VERSION ""

NS_ :

BS_:

BU_: ACC ACP Aux_Inv BEQ BMS BRC CAMERA CCS CLU CLUSTER CM CRSH EBS ECAS EHP EHPS_Hi_OilPump EHPS_Lo_OilPump EWP_1 EWP_2 EWP_3 FAM LDC MFC MFSM RAM TBOX TCU Tester VCU

BO_ 1298 VCU_HMU: 8 VCU
 SG_ CF_Vcu_H2TnkVlv1Open : 0|1@1+ (1,0) [0|1] "" Vector__XXX
 SG_ CF_Vcu_H2TnkVlv2Open : 1|1@1+ (1,0) [0|1] "" Vector__XXX
 SG_ CF_Vcu_H2TnkVlv3Open : 2|1@1+ (1,0) [0|1] "" Vector__XXX
 SG_ CF_Vcu_H2TnkVlv4Open : 3|1@1+ (1,0) [0|1] "" Vector__XXX
 SG_ CF_Vcu_H2TnkVlv5Open : 4|1@1+ (1,0) [0|1] "" Vector__XXX
 SG_ CF_Vcu_H2TnkVlv6Open : 5|1@1+ (1,0) [0|1] "" Vector__XXX
 SG_ CF_Vcu_H2TnkVlv7Open : 6|1@1+ (1,0) [0|1] "" Vector__XXX
 SG_ CF_Vcu_H2TnkVlv8Open : 7|1@1+ (1,0) [0|1] "" Vector__XXX
 SG_ CF_Vcu_VehSt : 8|1@1+ (1,0) [0|1] "" Vector__XXX
 SG_ CF_Vcu_VehWu : 9|1@1+ (1,0) [0|1] "" Vector__XXX
 SG_ CF_Vcu_VehHybFcMde : 10|1@1+ (1,0) [0|1] "" Vector__XXX
 SG_ CF_Vcu_FuelDrOpnUn : 11|1@1+ (1,0) [0|1] "" Vector__XXX
 SG_ CR_Vcu_VehStpHr : 16|8@1+ (1,0) [0|255] "" Vector__XXX
 SG_ CF_Vcu_H2TnkVlv9Open : 24|1@1+ (1,0) [0|1] "" Vector__XXX
 SG_ CF_Vcu_H2TnkVlv10Open : 25|1@1+ (1,0) [0|1] "" Vector__XXX
 SG_ CF_Vcu_H2TnkVlv11Open : 26|1@1+ (1,0) [0|1] "" Vector__XXX
 SG_ CF_Vcu_H2TnkVlv12Open : 27|1@1+ (1,0) [0|1] "" Vector__XXX

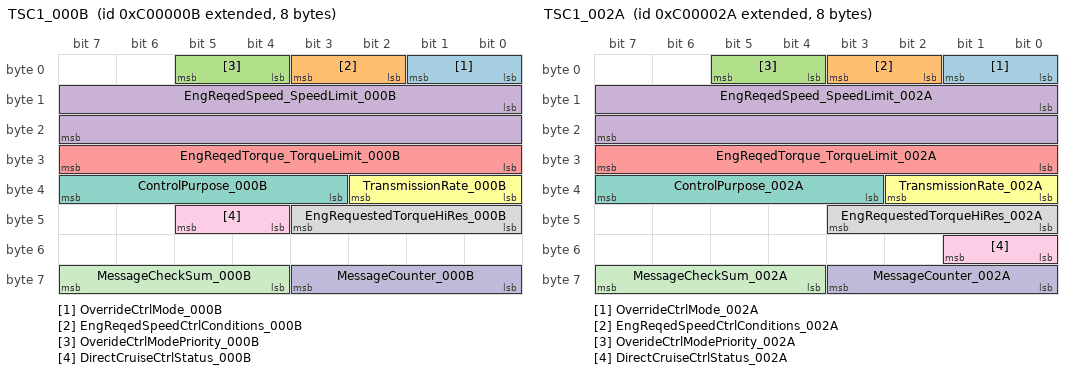
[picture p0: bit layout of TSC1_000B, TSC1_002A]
BO_ 2348810251 TSC1_000B: 8 EBS
 SG_ OverrideCtrlMode_000B : 0|2@1+ (1,0) [0|3] "" VCU
 SG_ EngReqedSpeedCtrlConditions_000B : 2|2@1+ (1,0) [0|3] "" VCU
 SG_ OverideCtrlModePriority_000B : 4|2@1+ (1,0) [0|3] "" VCU
 SG_ EngReqedSpeed_SpeedLimit_000B : 8|16@1+ (0.125,0) [0|8031.88] "rpm" VCU
 SG_ EngReqedTorque_TorqueLimit_000B : 24|8@1+ (1,-125) [-125|125] "%" VCU
 SG_ TransmissionRate_000B : 32|3@1+ (1,0) [0|7] "" VCU
 SG_ ControlPurpose_000B : 35|5@1+ (1,0) [0|31] "" VCU
 SG_ EngRequestedTorqueHiRes_000B : 40|4@1+ (0.125,0) [0|0.875] "%" VCU
 SG_ DirectCruiseCtrlStatus_000B : 44|2@1+ (1,0) [0|3] "" VCU
 SG_ MessageCounter_000B : 56|4@1+ (1,0) [0|15] "" VCU
 SG_ MessageCheckSum_000B : 60|4@1+ (1,0) [0|15] "" VCU

BO_ 2348810282 TSC1_002A: 8 ACC
 SG_ OverrideCtrlMode_002A : 0|2@1+ (1,0) [0|3] "" VCU
 SG_ EngReqedSpeedCtrlConditions_002A : 2|2@1+ (1,0) [0|3] "" VCU
 SG_ OverideCtrlModePriority_002A : 4|2@1+ (1,0) [0|3] "" VCU
 SG_ EngReqedSpeed_SpeedLimit_002A : 8|16@1+ (0.125,0) [0|8031.88] "rpm" VCU
 SG_ EngReqedTorque_TorqueLimit_002A : 24|8@1+ (1,-125) [-125|125] "%" VCU
 SG_ TransmissionRate_002A : 32|3@1+ (1,0) [0|7] "" VCU
 SG_ ControlPurpose_002A : 35|5@1+ (1,0) [0|31] "" VCU
 SG_ EngRequestedTorqueHiRes_002A : 40|4@1+ (0.125,0) [0|0.875] "%" VCU
 SG_ DirectCruiseCtrlStatus_002A : 48|2@1+ (1,0) [0|3] "" VCU
 SG_ MessageCounter_002A : 56|4@1+ (1,0) [0|15] "" VCU
 SG_ MessageCheckSum_002A : 60|4@1+ (1,0) [0|15] "" VCU

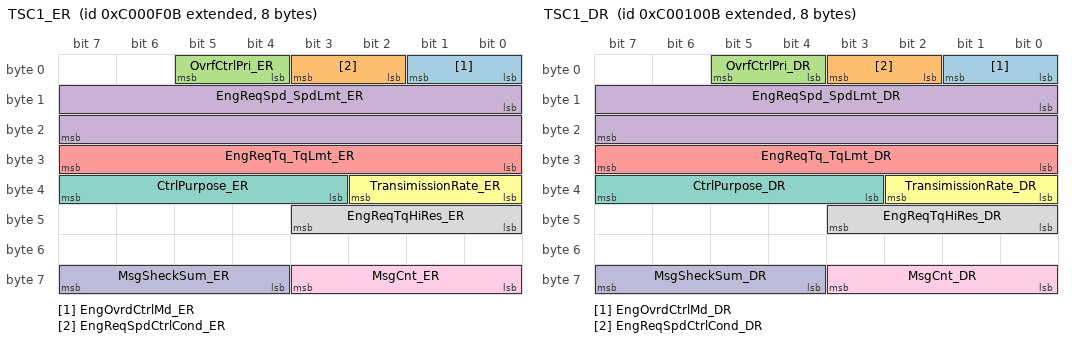
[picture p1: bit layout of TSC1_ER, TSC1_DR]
BO_ 2348814091 TSC1_ER: 8 EBS
 SG_ EngOvrdCtrlMd_ER : 0|2@1+ (1,0) [0|3] "" VCU
 SG_ EngReqSpdCtrlCond_ER : 2|2@1+ (1,0) [0|3] "" VCU
 SG_ OvrfCtrlPri_ER : 4|2@1+ (1,0) [0|3] "" VCU
 SG_ EngReqSpd_SpdLmt_ER : 8|16@1+ (0.125,0) [0|8031.88] "" VCU
 SG_ EngReqTq_TqLmt_ER : 24|8@1+ (1,-125) [-125|125] "" VCU
 SG_ TransimissionRate_ER : 32|3@1+ (1,0) [0|7] "" VCU
 SG_ CtrlPurpose_ER : 35|5@1+ (1,0) [0|31] "" VCU
 SG_ EngReqTqHiRes_ER : 40|4@1+ (0.125,0) [0|0.875] "" VCU
 SG_ MsgCnt_ER : 56|4@1+ (1,0) [0|15] "" VCU
 SG_ MsgSheckSum_ER : 60|4@1+ (1,0) [0|15] "" VCU

BO_ 2348814347 TSC1_DR: 8 EBS
 SG_ EngOvrdCtrlMd_DR : 0|2@1+ (1,0) [0|3] "" VCU
 SG_ EngReqSpdCtrlCond_DR : 2|2@1+ (1,0) [0|3] "" VCU
 SG_ OvrfCtrlPri_DR : 4|2@1+ (1,0) [0|3] "" VCU
 SG_ EngReqSpd_SpdLmt_DR : 8|16@1+ (0.125,0) [0|8031.88] "" VCU
 SG_ EngReqTq_TqLmt_DR : 24|8@1+ (1,-125) [-125|125] "" VCU
 SG_ TransimissionRate_DR : 32|3@1+ (1,0) [0|7] "" VCU
 SG_ CtrlPurpose_DR : 35|5@1+ (1,0) [0|31] "" VCU
 SG_ EngReqTqHiRes_DR : 40|4@1+ (0.125,0) [0|0.875] "" VCU
 SG_ MsgCnt_DR : 56|4@1+ (1,0) [0|15] "" VCU
 SG_ MsgSheckSum_DR : 60|4@1+ (1,0) [0|15] "" VCU

BO_ 2348876549 TC1_EATON: 8 MFSM
 SG_ TransmissionRequestedGear : 16|8@1+ (1,0) [0|255] "" VCU

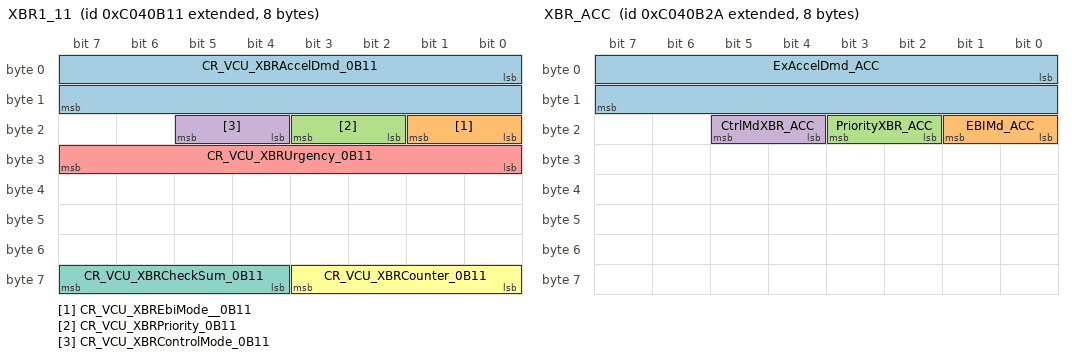
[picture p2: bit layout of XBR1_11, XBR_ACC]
BO_ 2349075217 XBR1_11: 8 VCU
 SG_ CR_VCU_XBRAccelDmd_0B11 : 0|16@1+ (0.000488281,-15.687) [-15.687|15.687] "" EBS
 SG_ CR_VCU_XBREbiMode__0B11 : 16|2@1+ (1,0) [0|3] "" EBS
 SG_ CR_VCU_XBRPriority_0B11 : 18|2@1+ (1,0) [0|3] "" EBS
 SG_ CR_VCU_XBRControlMode_0B11 : 20|2@1+ (1,0) [0|3] "" EBS
 SG_ CR_VCU_XBRUrgency_0B11 : 24|8@1+ (0.4,0) [0|100] "" EBS
 SG_ CR_VCU_XBRCounter_0B11 : 56|4@1+ (1,0) [0|15] "" EBS
 SG_ CR_VCU_XBRCheckSum_0B11 : 60|4@1+ (1,0) [0|15] "" EBS

BO_ 2349075242 XBR_ACC: 8 ACC
 SG_ ExAccelDmd_ACC : 0|16@1+ (0.0004883,-15.687) [-15.687|15.687] "" VCU
 SG_ EBIMd_ACC : 16|2@1+ (1,0) [0|2] "" VCU
 SG_ PriorityXBR_ACC : 18|2@1+ (1,0) [0|2] "" VCU
 SG_ CtrlMdXBR_ACC : 20|2@1+ (1,0) [0|2] "" VCU

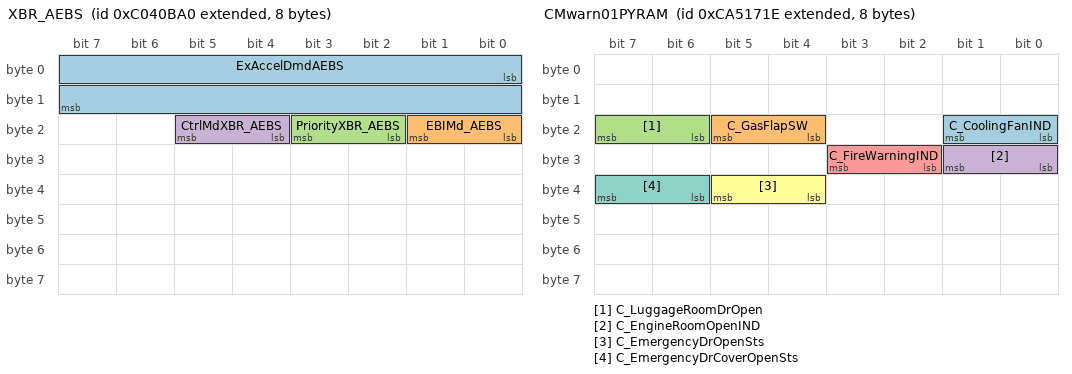
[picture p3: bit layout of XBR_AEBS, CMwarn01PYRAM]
BO_ 2349075360 XBR_AEBS: 8 CAMERA
 SG_ ExAccelDmdAEBS : 0|16@1+ (0.0004883,-15.687) [-15.687|15.687] "" VCU
 SG_ EBIMd_AEBS : 16|2@1+ (1,0) [0|2] "" VCU
 SG_ PriorityXBR_AEBS : 18|2@1+ (1,0) [0|2] "" VCU
 SG_ CtrlMdXBR_AEBS : 20|2@1+ (1,0) [0|2] "" VCU

BO_ 2359629598 CMwarn01PYRAM: 8 RAM
 SG_ C_CoolingFanIND : 16|2@1+ (1,0) [0|3] "" VCU
 SG_ C_GasFlapSW : 20|2@1+ (1,0) [0|3] "" VCU
 SG_ C_LuggageRoomDrOpen : 22|2@1+ (1,0) [0|3] "" VCU
 SG_ C_EngineRoomOpenIND : 24|2@1+ (1,0) [0|3] "" VCU
 SG_ C_FireWarningIND : 26|2@1+ (1,0) [0|3] "" VCU
 SG_ C_EmergencyDrOpenSts : 36|2@1+ (1,0) [0|3] "" VCU
 SG_ C_EmergencyDrCoverOpenSts : 38|2@1+ (1,0) [0|3] "" VCU

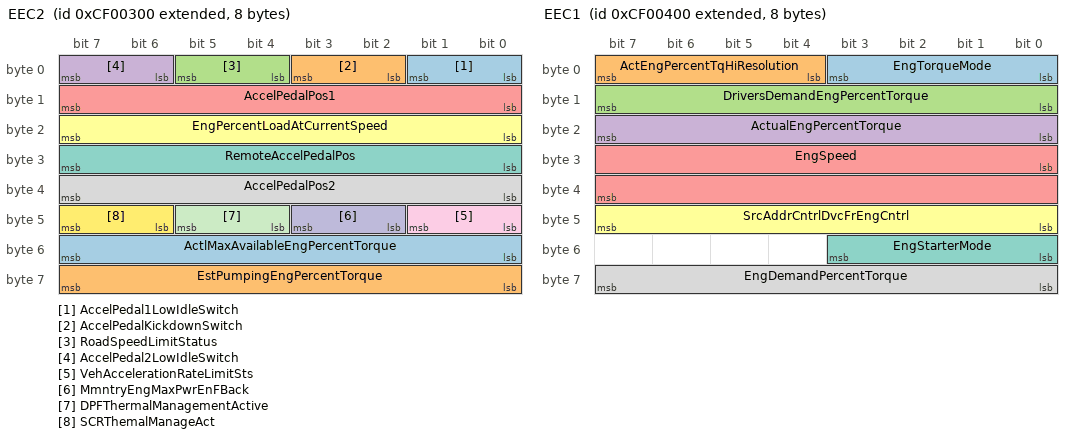
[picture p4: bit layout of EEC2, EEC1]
BO_ 2364539648 EEC2: 8 VCU
 SG_ AccelPedal1LowIdleSwitch : 0|2@1+ (1,0) [0|3] "" TCU
 SG_ AccelPedalKickdownSwitch : 2|2@1+ (1,0) [0|3] "" TCU
 SG_ RoadSpeedLimitStatus : 4|2@1+ (1,0) [0|3] "" TCU
 SG_ AccelPedal2LowIdleSwitch : 6|2@1+ (1,0) [0|3] "" TCU
 SG_ AccelPedalPos1 : 8|8@1+ (0.4,0) [0|100] "%" TCU,MFC,FAM
 SG_ EngPercentLoadAtCurrentSpeed : 16|8@1+ (1,0) [0|250] "%" TCU
 SG_ RemoteAccelPedalPos : 24|8@1+ (0.4,0) [0|100] "%" TCU
 SG_ AccelPedalPos2 : 32|8@1+ (0.4,0) [0|100] "%" TCU
 SG_ VehAccelerationRateLimitSts : 40|2@1+ (1,0) [0|3] "" TCU
 SG_ MmntryEngMaxPwrEnFBack : 42|2@1+ (1,0) [0|3] "" TCU
 SG_ DPFThermalManagementActive : 44|2@1+ (1,0) [0|3] "" TCU
 SG_ SCRThemalManageAct : 46|2@1+ (1,0) [0|3] "" TCU
 SG_ ActlMaxAvailableEngPercentTorque : 48|8@1+ (0.4,0) [0|100] "%" TCU
 SG_ EstPumpingEngPercentTorque : 56|8@1+ (1,-125) [-125|125] "%" TCU

BO_ 2364539904 EEC1: 8 VCU
 SG_ EngTorqueMode : 0|4@1+ (1,0) [0|15] "" Vector__XXX
 SG_ ActEngPercentTqHiResolution : 4|4@1+ (0.125,0) [0|0.875] "%" Vector__XXX
 SG_ DriversDemandEngPercentTorque : 8|8@1+ (1,-125) [-125|125] "%" Vector__XXX
 SG_ ActualEngPercentTorque : 16|8@1+ (1,-125) [-125|125] "%" Vector__XXX
 SG_ EngSpeed : 24|16@1+ (0.125,0) [0|8031.88] "rpm" Vector__XXX
 SG_ SrcAddrCntrlDvcFrEngCntrl : 40|8@1+ (1,0) [0|255] "" Vector__XXX
 SG_ EngStarterMode : 48|4@1+ (1,0) [0|15] "" Vector__XXX
 SG_ EngDemandPercentTorque : 56|8@1+ (1,-125) [-125|125] "%" Vector__XXX

BO_ 2364550954 AEBS_2A: 8 ACC
 SG_ AEBSState_2F2A : 0|4@1+ (1,0) [0|15] "" VCU
 SG_ CollisionWarningStatus_2F2A : 4|4@1+ (1,0) [0|15] "" VCU
 SG_ RelativeObjDetForAEBS_2F2A : 8|3@1+ (1,0) [0|7] "" VCU

BO_ 2365484270 TCO1_EE: 8 VCU
 SG_ TachographVehicleSpeed : 48|16@1+ (0.0039063,0) [0|250.996] "" Vector__XXX

BO_ 2432593706 ACC1: 8 ACC
 SG_ AdaptiveCruiseCtrlMode : 24|3@1+ (1,0) [0|7] "" VCU
 SG_ AdaptiveCruiseCtrlSetDisanceMode : 27|3@1+ (1,0) [0|7] "" VCU
 SG_ RoadCurvature : 32|16@1+ (1,0) [0|65535] "" VCU
 SG_ ACCTargetDetected : 48|2@1+ (0.0078125,-250) [-250|251.992] "" VCU
 SG_ ACCSystemShutoffWarning : 50|2@1+ (1,0) [0|3] "" VCU
 SG_ ACCDistanceAlertSignal : 52|2@1+ (1,0) [0|3] "" VCU
 SG_ ForwardCollisionWarning : 54|2@1+ (1,0) [0|3] "" VCU
 SG_ SCC_Type_Info : 60|2@1+ (1,0) [0|3] "" VCU

BO_ 2499739887 TX_MSG_CAN0: 8 VCU
 SG_ Signal_TX_CAN0 : 0|8@1+ (1,0) [0|255] "" Vector__XXX

BO_ 2499739897 RX_MSG_CAN0: 8 Tester
 SG_ Signal_RX_CAN0 : 0|8@1+ (1,0) [0|255] "" VCU

BO_ 2499748079 TX_MSG_CAN1: 8 VCU
 SG_ Signal_TX_CAN1 : 0|8@1+ (1,0) [0|1] "" Vector__XXX

BO_ 2499748089 RX_MSG_CAN1: 8 Tester
 SG_ Signal_RX_CAN1 : 0|8@1+ (1,0) [0|1] "" VCU

BO_ 2550876911 VCU2TBOX: 8 VCU
 SG_ VCU_FuelCsmpt : 16|16@1+ (0.1,0) [0|600] "kg/100km" TBOX

BO_ 2560814937 CRSH_VCU: 8 CRSH
 SG_ CRSH_CshXaxisAcceleration : 0|16@1+ (0.1,-10) [-10|10] "" VCU
 SG_ CRSH_CshYaxisAcceleration : 16|16@1+ (0.1,-10) [-10|10] "" VCU

BO_ 2565537791 RQST: 3 VCU
 SG_ LSBReqPGN : 0|8@1+ (1,0) [0|255] "" Vector__XXX
 SG_ ReqPGN : 8|8@1+ (1,0) [0|255] "" Vector__XXX
 SG_ MSBReqPGN : 16|8@1+ (1,0) [0|255] "" Vector__XXX

BO_ 2565603072 TPDT_EC: 8 VCU
 SG_ SequenceNum_EC : 0|8@1+ (1,0) [0|255] "" Vector__XXX
 SG_ PacketizedData_EC : 8|56@1+ (1,0) [0|7.20575940379279e+16] "" Vector__XXX

BO_ 2565603087 TPDT_RCER: 8 VCU
 SG_ SequenceNum_RCER : 0|8@1+ (1,0) [0|255] "" Vector__XXX
 SG_ PacketizedData_RCER : 8|56@1+ (1,0) [0|7.20575940379279e+16] "" Vector__XXX

BO_ 2565603088 TPDT_RCDR: 8 VCU
 SG_ SequenceNum_RCDR : 0|8@1+ (1,0) [0|255] "" Vector__XXX
 SG_ PacketizedData_RCDR : 8|56@1+ (1,0) [0|7.20575940379279e+16] "" Vector__XXX

BO_ 2565603311 TPDT_VCU: 8 VCU
 SG_ SequenceNum_VCU : 0|8@1+ (1,0) [0|252] "" Vector__XXX
 SG_ PacketizedData_VCU : 8|56@1+ (1,0) [0|0] "" Vector__XXX

BO_ 2565668608 TPCM_EC: 8 VCU
 SG_ ControlByte_EC : 0|8@1+ (1,0) [0|255] "" Vector__XXX
 SG_ TotalMessageSize_EC : 8|16@1+ (1,0) [0|0] "" Vector__XXX
 SG_ TotalNumberOfPacket_EC : 24|8@1+ (1,0) [0|0] "" Vector__XXX
 SG_ PGNumber_EC : 40|24@1+ (1,0) [0|16777200] "" Vector__XXX

BO_ 2565668623 TPCM_RCER: 8 VCU
 SG_ ControlByte_RCER : 0|8@1+ (1,0) [0|255] "" Vector__XXX
 SG_ TotalMessageSize_RCER : 8|16@1+ (1,0) [0|0] "" Vector__XXX
 SG_ TotalNumberOfPacket_RCER : 24|8@1+ (1,0) [0|0] "" Vector__XXX
 SG_ PGNumber_RCER : 40|24@1+ (1,0) [0|16777200] "" Vector__XXX

BO_ 2565668624 TPCM_RCDR: 8 VCU
 SG_ ControlByte_RCDR : 0|8@1+ (1,0) [0|255] "" Vector__XXX
 SG_ TotalMessageSize_RCDR : 8|16@1+ (1,0) [0|0] "" Vector__XXX
 SG_ TotalNumberOfPacket_RCDR : 24|8@1+ (1,0) [0|0] "" Vector__XXX
 SG_ PGNumber_RCDR : 40|24@1+ (1,0) [0|16777200] "" Vector__XXX

BO_ 2565668847 TPCM_VCU: 8 VCU
 SG_ ControlByte_VCU : 0|8@1+ (1,0) [0|255] "" Vector__XXX
 SG_ TotalMessageSize_VCU : 8|16@1+ (1,0) [0|0] "" Vector__XXX
 SG_ TotalNumberOfPacket_VCU : 24|8@1+ (1,0) [0|0] "" Vector__XXX
 SG_ PGNumber_VCU : 40|24@1+ (1,0) [0|16777200] "" Vector__XXX

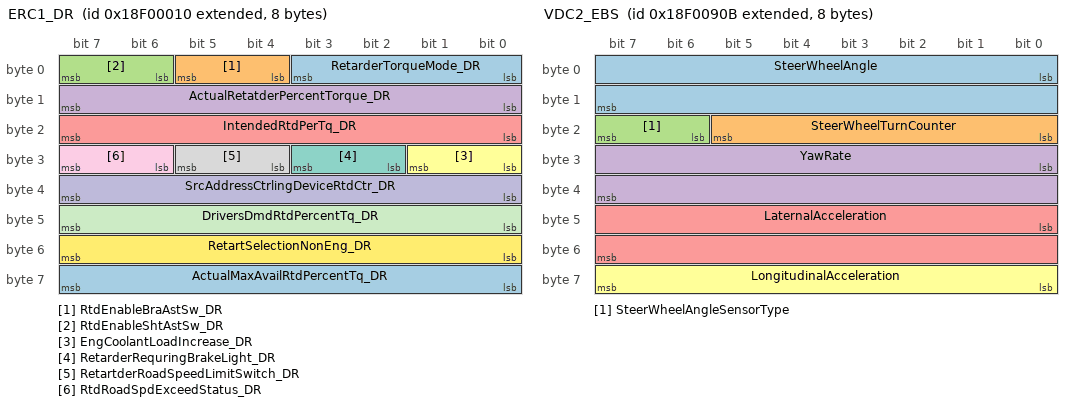
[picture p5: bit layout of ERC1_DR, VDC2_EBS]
BO_ 2565865488 ERC1_DR: 8 VCU
 SG_ RetarderTorqueMode_DR : 0|4@1+ (1,0) [0|15] "" Vector__XXX
 SG_ RtdEnableBraAstSw_DR : 4|2@1+ (1,0) [0|3] "" Vector__XXX
 SG_ RtdEnableShtAstSw_DR : 6|2@1+ (1,0) [0|3] "" Vector__XXX
 SG_ ActualRetatderPercentTorque_DR : 8|8@1+ (1,-125) [-125|125] "%" Vector__XXX
 SG_ IntendedRtdPerTq_DR : 16|8@1+ (1,-125) [-125|125] "%" Vector__XXX
 SG_ EngCoolantLoadIncrease_DR : 24|2@1+ (1,0) [0|3] "" Vector__XXX
 SG_ RetarderRequringBrakeLight_DR : 26|2@1+ (1,0) [0|3] "" Vector__XXX
 SG_ RetartderRoadSpeedLimitSwitch_DR : 28|2@1+ (1,0) [0|3] "" Vector__XXX
 SG_ RtdRoadSpdExceedStatus_DR : 30|2@1+ (1,0) [0|3] "" Vector__XXX
 SG_ SrcAddressCtrlingDeviceRtdCtr_DR : 32|8@1+ (1,0) [0|255] "" Vector__XXX
 SG_ DriversDmdRtdPercentTq_DR : 40|8@1+ (1,-125) [-125|125] "%" Vector__XXX
 SG_ RetartSelectionNonEng_DR : 48|8@1+ (0.4,0) [0|100] "%" Vector__XXX
 SG_ ActualMaxAvailRtdPercentTq_DR : 56|8@1+ (1,-125) [-125|125] "%" Vector__XXX

BO_ 2565865739 EBC1: 8 EBS
 SG_ ASREngCtrlActive : 0|2@1+ (1,0) [0|3] "" VCU
 SG_ ASRBrakeCtrlActive : 2|2@1+ (1,0) [0|3] "" VCU
 SG_ AntiLockBrakingActive : 4|2@1+ (1,0) [0|3] "" VCU
 SG_ EBSBrakeSwitch : 6|2@1+ (1,0) [0|3] "" VCU
 SG_ BrakePedalPosition : 8|8@1+ (0.4,0) [0|100] "%" VCU
 SG_ ABSOffroadSwitch : 16|2@1+ (1,0) [0|3] "" VCU
 SG_ ASROffroadSwitch : 18|2@1+ (1,0) [0|3] "" VCU
 SG_ ASRHillHolderSwitch : 20|2@1+ (1,0) [0|3] "" VCU
 SG_ TractionCtrlOverrideSwitch : 22|2@1+ (1,0) [0|3] "" VCU
 SG_ AccelInterlockSwitch : 24|2@1+ (1,0) [0|3] "" VCU
 SG_ EngDeratingSwitch : 26|2@1+ (1,0) [0|3] "" VCU
 SG_ EngAuxShutdownSwitch : 28|2@1+ (1,0) [0|3] "" VCU
 SG_ RemoteAccelEnableSwitch : 30|2@1+ (1,0) [0|3] "" VCU
 SG_ EngRetarderSelection : 32|8@1+ (0.4,0) [0|100] "%" VCU
 SG_ ABSFullyOperational : 40|2@1+ (1,0) [0|3] "" VCU
 SG_ EBSRedWarningSignal : 42|2@1+ (1,0) [0|3] "" VCU
 SG_ ABS_EBSAmberWarningSignal : 44|2@1+ (1,0) [0|3] "" VCU
 SG_ ATC_ASRInformationSignal : 46|2@1+ (1,0) [0|3] "" VCU
 SG_ SrcAddrOfCtrllingDvcFrBrkCntrl : 48|8@1+ (1,0) [0|255] "" VCU
 SG_ HaltBrakeSwitch : 58|2@1+ (1,0) [0|3] "" VCU
 SG_ TrailerABSStatus : 60|2@1+ (1,0) [0|3] "" VCU
 SG_ TrctrMntdTrilerASWarningSignal : 62|2@1+ (1,0) [0|3] "" VCU

BO_ 2565865967 EBC1_X: 8 VCU
 SG_ CF_VCU_HillHolderSwitch : 20|2@1+ (1,0) [0|3] "" EBS

BO_ 2565867787 VDC2_EBS: 8 EBS
 SG_ SteerWheelAngle : 0|16@1+ (0.000976563,-31.374) [-31.374|31.374] "rad" VCU
 SG_ SteerWheelTurnCounter : 16|6@1+ (1,-32) [-32|29] "turns" VCU
 SG_ SteerWheelAngleSensorType : 22|2@1+ (1,0) [0|3] "" VCU
 SG_ YawRate : 24|16@1+ (0.00012207,-3.92) [-3.92|3.92] "rad/s" VCU
 SG_ LaternalAcceleration : 40|16@1+ (0.000488281,-15.687) [-15.687|15.687] "m/s" VCU
 SG_ LongitudinalAcceleration : 56|8@1+ (0.1,-12.5) [-12.5|12.5] "m/s" VCU

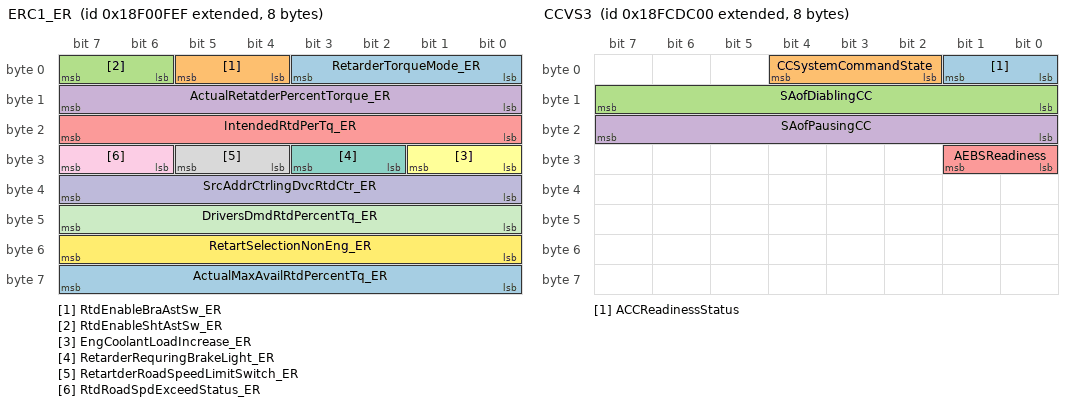
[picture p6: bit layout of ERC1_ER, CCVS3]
BO_ 2565869551 ERC1_ER: 8 VCU
 SG_ RetarderTorqueMode_ER : 0|4@1+ (1,0) [0|15] "" Vector__XXX
 SG_ RtdEnableBraAstSw_ER : 4|2@1+ (1,0) [0|3] "" Vector__XXX
 SG_ RtdEnableShtAstSw_ER : 6|2@1+ (1,0) [0|3] "" Vector__XXX
 SG_ ActualRetatderPercentTorque_ER : 8|8@1+ (1,-125) [-125|125] "%" Vector__XXX
 SG_ IntendedRtdPerTq_ER : 16|8@1+ (1,-125) [-125|125] "%" Vector__XXX
 SG_ EngCoolantLoadIncrease_ER : 24|2@1+ (1,0) [0|3] "" Vector__XXX
 SG_ RetarderRequringBrakeLight_ER : 26|2@1+ (1,0) [0|3] "" Vector__XXX
 SG_ RetartderRoadSpeedLimitSwitch_ER : 28|2@1+ (1,0) [0|3] "" Vector__XXX
 SG_ RtdRoadSpdExceedStatus_ER : 30|2@1+ (1,0) [0|3] "" Vector__XXX
 SG_ SrcAddrCtrlingDvcRtdCtr_ER : 32|8@1+ (1,0) [0|255] "" Vector__XXX
 SG_ DriversDmdRtdPercentTq_ER : 40|8@1+ (1,-125) [-125|125] "%" Vector__XXX
 SG_ RetartSelectionNonEng_ER : 48|8@1+ (0.4,0) [0|100] "%" Vector__XXX
 SG_ ActualMaxAvailRtdPercentTq_ER : 56|8@1+ (1,-125) [-125|125] "%" Vector__XXX

BO_ 2565877003 ACCS: 8 EBS
 SG_ ACCS_LongitudialAccel : 16|16@1+ (0.01,-320) [-320|320] "m/s2" VCU

BO_ 2566708224 CCVS3: 8 VCU
 SG_ ACCReadinessStatus : 0|2@1+ (1,0) [0|3] "" ACC
 SG_ CCSystemCommandState : 2|3@1+ (1,0) [0|7] "" ACC
 SG_ SAofDiablingCC : 8|8@1+ (1,0) [0|255] "" ACC
 SG_ SAofPausingCC : 16|8@1+ (1,0) [0|255] "" ACC
 SG_ AEBSReadiness : 24|2@1+ (1,0) [0|3] "" ACC

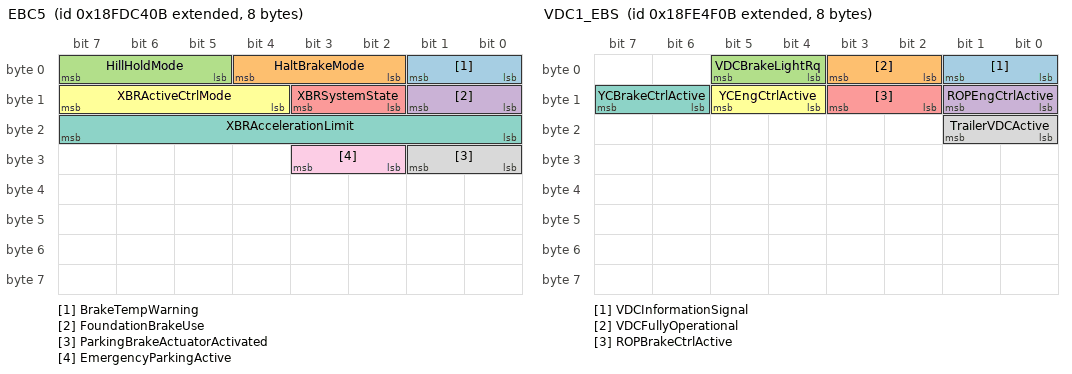
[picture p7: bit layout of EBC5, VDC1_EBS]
BO_ 2566767627 EBC5: 8 EBS
 SG_ BrakeTempWarning : 0|2@1+ (1,0) [0|3] "" VCU
 SG_ HaltBrakeMode : 2|3@1+ (1,0) [0|7] "" VCU
 SG_ HillHoldMode : 5|3@1+ (1,0) [0|7] "" VCU
 SG_ FoundationBrakeUse : 8|2@1+ (1,0) [0|3] "" VCU
 SG_ XBRSystemState : 10|2@1+ (1,0) [0|3] "" VCU
 SG_ XBRActiveCtrlMode : 12|4@1+ (1,0) [0|15] "" VCU
 SG_ XBRAccelerationLimit : 16|8@1+ (0.1,-12.5) [-12.5|12.5] "m/s^2" VCU
 SG_ ParkingBrakeActuatorActivated : 24|2@1+ (1,0) [0|3] "" VCU
 SG_ EmergencyParkingActive : 26|2@1+ (1,0) [0|3] "" VCU

BO_ 2566793775 VW: 8 ECAS
 SG_ AxleLocation : 0|8@1+ (1,0) [0|255] "" VCU
 SG_ AxleWeight : 8|16@1+ (0.5,0) [0|32127.5] "kg" VCU

BO_ 2566803211 VDC1_EBS: 8 EBS
 SG_ VDCInformationSignal : 0|2@1+ (1,0) [0|3] "" VCU
 SG_ VDCFullyOperational : 2|2@1+ (1,0) [0|3] "" VCU
 SG_ VDCBrakeLightRq : 4|2@1+ (1,0) [0|3] "" VCU
 SG_ ROPEngCtrlActive : 8|2@1+ (1,0) [0|3] "" VCU
 SG_ ROPBrakeCtrlActive : 10|2@1+ (1,0) [0|3] "" VCU
 SG_ YCEngCtrlActive : 12|2@1+ (1,0) [0|3] "" VCU
 SG_ YCBrakeCtrlActive : 14|2@1+ (1,0) [0|3] "" VCU
 SG_ TrailerVDCActive : 16|2@1+ (1,0) [0|3] "" VCU

BO_ 2566803761 ACC2: 8 CM
 SG_ ACCUsageDemand : 0|2@1+ (1,0) [0|3] "" VCU
 SG_ RequestedACCDistantMd : 5|3@1+ (1,0) [0|7] "" VCU

BO_ 2566810647 TCO1: 8 VCU
 SG_ WhkBasdSpeed : 48|16@1+ (0.00390625,0) [0|255] "" EHPS_Hi_OilPump,EHPS_Lo_OilPump

BO_ 2566811659 CVW: 8 EBS
 SG_ PoweredVehicleWeight : 0|16@1+ (10,0) [0|642550] "kg" VCU
 SG_ GrossCombinationVehicleWeight : 16|16@1+ (10,0) [0|642550] "kg" VCU

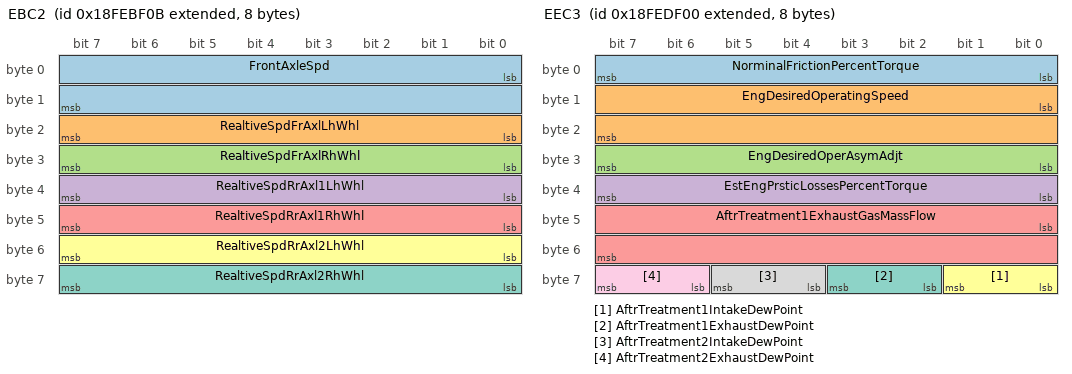
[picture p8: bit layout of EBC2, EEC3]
BO_ 2566831883 EBC2: 8 EBS
 SG_ FrontAxleSpd : 0|16@1+ (0.00390625,0) [0|250.996] "" VCU
 SG_ RealtiveSpdFrAxlLhWhl : 16|8@1+ (0.0625,-7.8125) [-7.8125|7.8125] "" VCU
 SG_ RealtiveSpdFrAxlRhWhl : 24|8@1+ (0.0625,-7.8125) [-7.8125|7.8125] "" VCU
 SG_ RealtiveSpdRrAxl1LhWhl : 32|8@1+ (0.0625,-7.8125) [-7.8125|7.8125] "" VCU
 SG_ RealtiveSpdRrAxl1RhWhl : 40|8@1+ (0.0625,-7.8125) [-7.8125|7.8125] "" VCU
 SG_ RealtiveSpdRrAxl2LhWhl : 48|8@1+ (0.0625,-7.8125) [-7.8125|7.8125] "" VCU
 SG_ RealtiveSpdRrAxl2RhWhl : 56|8@1+ (0.0625,-7.8125) [-7.8125|7.8125] "" VCU

BO_ 2566834927 DM1_VCU: 18 VCU
 SG_ ProtectLampStatus_VCU : 0|2@1+ (1,0) [0|3] "" CLUSTER
 SG_ AmberWarnLampSts_VCU : 2|2@1+ (1,0) [0|3] "" CLUSTER
 SG_ RedStopLampStatus_VCU : 4|2@1+ (1,0) [0|3] "" CLUSTER
 SG_ MalFuncIndiLampSts_VCU : 6|2@1+ (1,0) [0|3] "" CLUSTER
 SG_ FlashProtectLamp_VCU : 8|2@1+ (1,0) [0|3] "" CLUSTER
 SG_ FlashAmberWarnLamp_VCU : 10|2@1+ (1,0) [0|3] "" CLUSTER
 SG_ FlashRedStopLamp_VCU : 12|2@1+ (1,0) [0|3] "" CLUSTER
 SG_ FlashMalFuncIndiLamp_VCU : 14|2@1+ (1,0) [0|3] "" CLUSTER
 SG_ DTC1_VCU : 16|32@1+ (1,0) [0|4294967295] "" CLUSTER
 SG_ DTC2_VCU : 48|32@1+ (1,0) [0|4294967295] "" CLUSTER
 SG_ DTC3_VCU : 80|32@1+ (1,0) [0|4294967295] "" CLUSTER
 SG_ DTC4_VCU : 112|32@1+ (1,0) [0|4294967295] "" CLUSTER

BO_ 2566838758 EI2: 8 CM
 SG_ StartSwitch_CrankingSignal : 2|2@1+ (1,0) [0|3] "" VCU

BO_ 2566840064 EEC3: 8 VCU
 SG_ NorminalFrictionPercentTorque : 0|8@1+ (1,-125) [-125|125] "%" Vector__XXX
 SG_ EngDesiredOperatingSpeed : 8|16@1+ (0.125,0) [0|8031.88] "rpm" Vector__XXX
 SG_ EngDesiredOperAsymAdjt : 24|8@1+ (1,0) [0|250] "" Vector__XXX
 SG_ EstEngPrsticLossesPercentTorque : 32|8@1+ (1,-125) [-125|125] "%" Vector__XXX
 SG_ AftrTreatment1ExhaustGasMassFlow : 40|16@1+ (0.2,0) [0|12851] "kg/h" Vector__XXX
 SG_ AftrTreatment1IntakeDewPoint : 56|2@1+ (1,0) [0|3] "" Vector__XXX
 SG_ AftrTreatment1ExhaustDewPoint : 58|2@1+ (1,0) [0|3] "" Vector__XXX
 SG_ AftrTreatment2IntakeDewPoint : 60|2@1+ (1,0) [0|3] "" Vector__XXX
 SG_ AftrTreatment2ExhaustDewPoint : 62|2@1+ (1,0) [0|3] "" Vector__XXX

BO_ 2566840591 RC_ER: 19 VCU
 SG_ RetarderType_ER : 0|4@1+ (1,0) [0|15] "" Vector__XXX
 SG_ RetarderLocation_ER : 4|4@1+ (1,0) [0|15] "" Vector__XXX
 SG_ RetarderCtrlMethod_ER : 8|8@1+ (1,0) [0|250] "steps" Vector__XXX
 SG_ RetartderSpeedAtIdlePoint1_ER : 16|16@1+ (0.125,0) [0|8031.88] "rpm" Vector__XXX
 SG_ PercentTorqueAtIdlePoint1_ER : 32|8@1+ (1,-125) [-125|125] "%" Vector__XXX
 SG_ MaxRetarderSpeedPoint2 : 40|16@1+ (0.125,0) [0|8031.88] "rpm" Vector__XXX
 SG_ PercentTorqueAtMaxSpeedPoint2_ER : 56|8@1+ (1,-125) [-125|125] "%" Vector__XXX
 SG_ RetartderSpeedAtPoint3_ER : 64|16@1+ (0.125,0) [0|8031.88] "rpm" Vector__XXX
 SG_ PercentTorqueAtPoint3_ER : 80|8@1+ (1,-125) [-125|125] "%" Vector__XXX
 SG_ RetartderSpeedAtPoint4_ER : 88|16@1+ (0.125,0) [0|8031.88] "rpm" Vector__XXX
 SG_ PercentTorqueAtPoint4_ER : 104|8@1+ (1,-125) [-125|125] "%" Vector__XXX
 SG_ RtdSpdAtPeakTorquePoint5_ER : 112|16@1+ (0.125,0) [0|8031.88] "rpm" Vector__XXX
 SG_ ReferenceRetarderTorque_ER : 128|16@1+ (1,0) [0|64255] "Nm" Vector__XXX
 SG_ PerTqAtPeakTorquePoint5_ER : 144|8@1+ (1,-125) [-125|125] "%" Vector__XXX

BO_ 2566840592 RC_DR: 19 VCU
 SG_ RetarderType_DR : 0|4@1+ (1,0) [0|15] "" Vector__XXX
 SG_ RetarderLocation_DR : 4|4@1+ (1,0) [0|15] "" Vector__XXX
 SG_ RetarderCtrlMethod_DR : 8|8@1+ (1,0) [0|250] "steps" Vector__XXX
 SG_ RetartderSpeedAtIdlePoint1_DR : 16|16@1+ (0.125,0) [0|8031.88] "rpm" Vector__XXX
 SG_ PercentTorqueAtIdlePoint1_DR : 32|8@1+ (1,-125) [-125|125] "%" Vector__XXX
 SG_ MaxRetarderSpeedPoint2_DR : 40|16@1+ (0.125,0) [0|8031.88] "rpm" Vector__XXX
 SG_ PercentTorqueAtMaxSpeedPoint2_DR : 56|8@1+ (1,-125) [-125|125] "%" Vector__XXX
 SG_ RetartderSpeedAtPoint3_DR : 64|16@1+ (0.125,0) [0|8031.88] "rpm" Vector__XXX
 SG_ PercentTorqueAtPoint3_DR : 80|8@1+ (1,-125) [-125|125] "%" Vector__XXX
 SG_ RetartderSpeedAtPoint4_DR : 88|16@1+ (0.125,0) [0|8031.88] "rpm" Vector__XXX
 SG_ PercentTorqueAtPoint4_DR : 104|8@1+ (1,-125) [-125|125] "%" Vector__XXX
 SG_ RtdSpdAtPeakTorquePoint5_DR : 112|16@1+ (0.125,0) [0|8031.88] "rpm" Vector__XXX
 SG_ ReferenceRetarderTorque_DR : 128|16@1+ (1,0) [0|64255] "Nm" Vector__XXX
 SG_ PerTqAtPeakTorquePoint5_DR : 144|8@1+ (1,-125) [-125|125] "%" Vector__XXX

BO_ 2566841088 EC_VCU: 39 VCU
 SG_ EngSeedAtIdlePoint1 : 0|16@1+ (0.125,0) [0|8031.88] "rpm" Vector__XXX
 SG_ EngPercentTorqueAtIdlePoint1 : 16|8@1+ (1,-125) [-125|125] "%" Vector__XXX
 SG_ EngSpeedAtPoint2 : 24|16@1+ (0.125,0) [0|8031.88] "rpm" Vector__XXX
 SG_ EngPercentTorqueAtPoint2 : 40|8@1+ (1,-125) [-125|125] "%" Vector__XXX
 SG_ EngSpeedAtPoint3 : 48|16@1+ (0.125,0) [0|8031.88] "rpm" Vector__XXX
 SG_ EngPercentTorqueAtPoint3 : 64|8@1+ (1,-125) [-125|125] "%" Vector__XXX
 SG_ EngSpeedAtPoint4 : 72|16@1+ (0.125,0) [0|8031.88] "rpm" Vector__XXX
 SG_ EngPercentTorqueAtPoint4 : 88|8@1+ (1,-125) [-125|125] "%" Vector__XXX
 SG_ EngSpeedAtPoint5 : 96|16@1+ (0.125,0) [0|8031.88] "rpm" Vector__XXX
 SG_ EngPercentTorqueAtPoint5 : 112|8@1+ (1,-125) [-125|125] "%" Vector__XXX
 SG_ EngSpeedAtHighIdlePoint6 : 120|16@1+ (0.125,0) [0|8031.88] "rpm" Vector__XXX
 SG_ EngGainOfEngSpeedGovernor : 136|16@1+ (1,-125) [-125|125] "%" Vector__XXX
 SG_ EngReferenceTorque : 152|16@1+ (1,0) [0|64255] "Nm" Vector__XXX
 SG_ EngMxMmntryOvrdSpdPoint7 : 168|16@1+ (0.125,0) [0|8031.88] "rpm" Vector__XXX
 SG_ EngMxMmntryOvrdTimeLmit : 184|6@1+ (1,0) [0|25] "sec" Vector__XXX
 SG_ EngRqdSpdCtrlRgnLowLimit : 192|8@1+ (10,0) [0|2500] "rpm" Vector__XXX
 SG_ EngRqdSpdCtrlRgnUpperLimit : 200|8@1+ (10,0) [0|2500] "rpm" Vector__XXX
 SG_ EngRqdTqCtrlRgnLowLimit : 208|8@1+ (1,-125) [-125|125] "%" Vector__XXX
 SG_ EngRqdTqCtrlRgnUpperLimit : 216|8@1+ (1,-125) [-125|125] "%" Vector__XXX

BO_ 2566844672 CCVS: 8 VCU
 SG_ TwoSpeedAxleSwitch : 0|2@1+ (1,0) [0|3] "" CCS,FAM,MFC,TCU
 SG_ ParkingBrakeSwitch : 2|2@1+ (1,0) [0|3] "" CCS,FAM,MFC,TCU
 SG_ CruiseCtrlPauseSwitch : 4|2@1+ (1,0) [0|3] "" CCS,FAM,MFC,TCU
 SG_ ParkBrakeReleaseInhibitReq : 6|2@1+ (1,0) [0|3] "" CCS,FAM,MFC,TCU
 SG_ WheelBasedVehicleSpeed : 8|16@1+ (0.0039063,0) [0|250.996] "km/h" CCS,FAM,MFC,TCU
 SG_ CruiseCtrlActive : 24|2@1+ (1,0) [0|3] "" CCS,FAM,MFC,TCU
 SG_ CruiseCtrlEnableSwitch : 26|2@1+ (1,0) [0|3] "" CCS,FAM,MFC,TCU
 SG_ BrakeSwitch : 28|2@1+ (1,0) [0|3] "" CCS,FAM,MFC,TCU
 SG_ ClutchSwitch : 30|2@1+ (1,0) [0|3] "" CCS,FAM,MFC,TCU
 SG_ CruiseCtrlSetSwitch : 32|2@1+ (1,0) [0|3] "" CCS,FAM,MFC,TCU
 SG_ CruiseCtrlCoastSwitch : 34|2@1+ (1,0) [0|3] "" CCS,FAM,MFC,TCU
 SG_ CruiseCtrlResumeSwitch : 36|2@1+ (1,0) [0|3] "" CCS,FAM,MFC,TCU
 SG_ CruiseCtrlAccelerateSwitch : 38|2@1+ (1,0) [0|3] "" CCS,FAM,MFC,TCU
 SG_ CruiseStrlSetSpeed : 40|8@1+ (1,0) [0|250] "km/h" CCS,FAM,MFC,TCU
 SG_ PTOGpvernorState : 48|5@1+ (1,0) [0|31] "" CCS,FAM,MFC,TCU
 SG_ CruiseCtrlStates : 53|3@1+ (1,0) [0|7] "" CCS,FAM,MFC,TCU
 SG_ EngIdleIncrementSwitch : 56|2@1+ (1,0) [0|3] "" CCS,FAM,MFC,TCU
 SG_ EngDecrementSwitch : 58|2@1+ (1,0) [0|3] "" CCS,FAM,MFC,TCU
 SG_ EngTestModeSwitch : 60|2@1+ (1,0) [0|3] "" CCS,FAM,MFC,TCU
 SG_ EngShutdownOverrideSwitch : 62|2@1+ (1,0) [0|3] "" CCS,FAM,MFC,TCU

BO_ 2566844683 HRW: 8 EBS
 SG_ FrontAxleLeftWheelSpeed : 0|16@1+ (0.00390625,0) [0|250.996] "km/h" VCU
 SG_ FrontAxleRightWheelSpeed : 16|16@1+ (0.00390625,0) [0|250.996] "km/h" VCU
 SG_ RearAxleLeftWheelSpeed : 32|16@1+ (0.00390625,0) [0|250.996] "km/h" VCU
 SG_ RearAxleRightWheelSpeed : 48|16@1+ (0.00390625,0) [0|250.996] "km/h" VCU

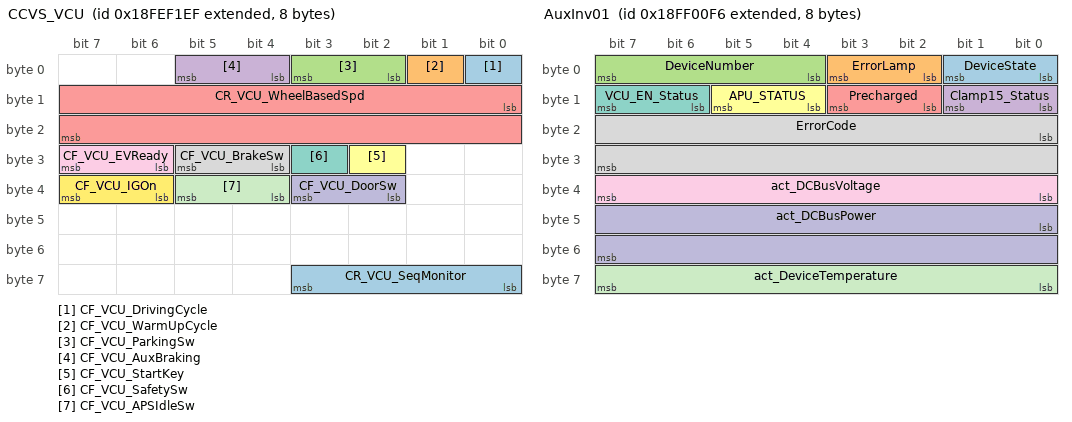
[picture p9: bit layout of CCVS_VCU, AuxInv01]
BO_ 2566844911 CCVS_VCU: 8 VCU
 SG_ CF_VCU_DrivingCycle : 0|1@1+ (1,0) [0|1] "" BMS
 SG_ CF_VCU_WarmUpCycle : 1|1@1+ (1,0) [0|1] "" BMS
 SG_ CF_VCU_ParkingSw : 2|2@1+ (1,0) [0|3] "" BMS
 SG_ CF_VCU_AuxBraking : 4|2@1+ (1,0) [0|3] "" BMS
 SG_ CR_VCU_WheelBasedSpd : 8|16@1+ (0.0039063,0) [0|250.996] "km/h" BMS
 SG_ CF_VCU_StartKey : 26|1@1+ (1,0) [0|1] "" BMS
 SG_ CF_VCU_SafetySw : 27|1@1+ (1,0) [0|1] "" BMS
 SG_ CF_VCU_BrakeSw : 28|2@1+ (1,0) [0|3] "" BMS
 SG_ CF_VCU_EVReady : 30|2@1+ (1,0) [0|1] "" BMS
 SG_ CF_VCU_DoorSw : 34|2@1+ (1,0) [0|3] "" BMS
 SG_ CF_VCU_APSIdleSw : 36|2@1+ (1,0) [0|1] "" BMS
 SG_ CF_VCU_IGOn : 38|2@1+ (1,0) [0|1] "" BMS
 SG_ CR_VCU_SeqMonitor : 56|4@1+ (1,0) [0|15] "" BMS

BO_ 2566848758 AuxInv01: 8 Aux_Inv
 SG_ DeviceState : 0|2@1+ (1,0) [0|3] "" VCU
 SG_ ErrorLamp : 2|2@1+ (1,0) [0|3] "" VCU
 SG_ DeviceNumber : 4|4@1+ (1,0) [0|15] "" VCU
 SG_ Clamp15_Status : 8|2@1+ (1,0) [0|3] "" VCU
 SG_ Precharged : 10|2@1+ (1,0) [0|3] "" VCU
 SG_ APU_STATUS : 12|2@1+ (1,0) [0|3] "" VCU
 SG_ VCU_EN_Status : 14|2@1+ (1,0) [0|3] "" VCU
 SG_ ErrorCode : 16|16@1+ (1,0) [0|65535] "" VCU
 SG_ act_DCBusVoltage : 32|8@1+ (4,0) [0|1000] "V" VCU
 SG_ act_DCBusPower : 40|16@1- (0.005,-160) [-160|161.275] "kw" VCU
 SG_ act_DeviceTemperature : 56|8@1- (1,-40) [-40|210] "℃" VCU

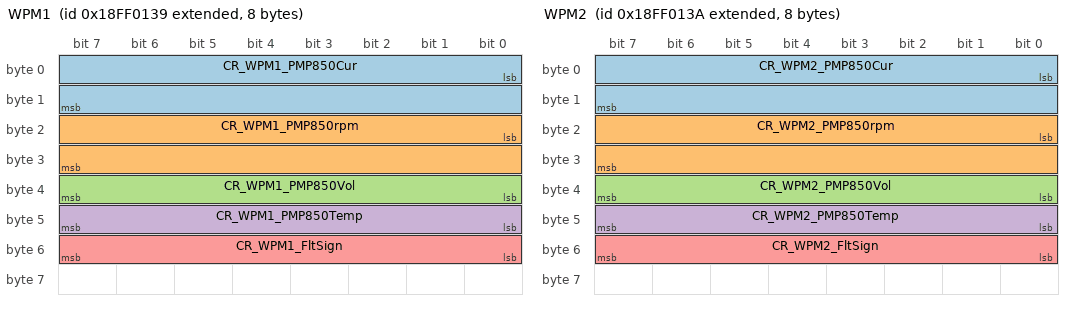
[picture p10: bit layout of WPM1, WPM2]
BO_ 2566848825 WPM1: 8 EWP_1
 SG_ CR_WPM1_PMP850Cur : 0|16@1+ (0.1,0) [0|6553.5] "A" VCU
 SG_ CR_WPM1_PMP850rpm : 16|16@1+ (1,0) [0|65535] "rpm" VCU
 SG_ CR_WPM1_PMP850Vol : 32|8@1+ (0.1,0) [0|25.5] "V" VCU
 SG_ CR_WPM1_PMP850Temp : 40|8@1+ (1,-50) [-50|205] "℃" VCU
 SG_ CR_WPM1_FltSign : 48|8@1+ (1,0) [0|255] "" VCU

BO_ 2566848826 WPM2: 8 EWP_2
 SG_ CR_WPM2_PMP850Cur : 0|16@1+ (0.1,0) [0|6553.5] "A" VCU
 SG_ CR_WPM2_PMP850rpm : 16|16@1+ (1,0) [0|65535] "rpm" VCU
 SG_ CR_WPM2_PMP850Vol : 32|8@1+ (0.1,0) [0|25.5] "V" VCU
 SG_ CR_WPM2_PMP850Temp : 40|8@1+ (1,-50) [-50|205] "℃" VCU
 SG_ CR_WPM2_FltSign : 48|8@1+ (1,0) [0|255] "" VCU

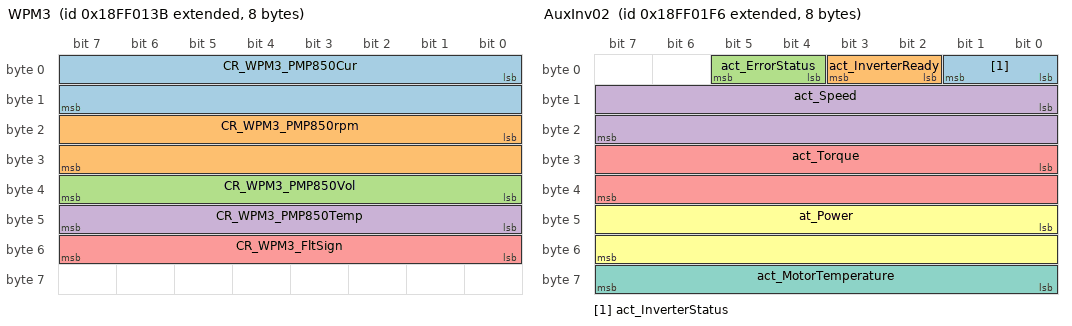
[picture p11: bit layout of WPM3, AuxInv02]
BO_ 2566848827 WPM3: 8 EWP_3
 SG_ CR_WPM3_PMP850Cur : 0|16@1+ (0.1,0) [0|6553.5] "A" VCU
 SG_ CR_WPM3_PMP850rpm : 16|16@1+ (1,0) [0|65535] "rpm" VCU
 SG_ CR_WPM3_PMP850Vol : 32|8@1+ (0.1,0) [0|25.5] "V" VCU
 SG_ CR_WPM3_PMP850Temp : 40|8@1+ (1,-50) [-50|205] "℃" VCU
 SG_ CR_WPM3_FltSign : 48|8@1+ (1,0) [0|255] "" VCU

BO_ 2566849014 AuxInv02: 8 Aux_Inv
 SG_ act_InverterStatus : 0|2@1+ (1,0) [0|3] "" VCU
 SG_ act_InverterReady : 2|2@1+ (1,0) [0|3] "" VCU
 SG_ act_ErrorStatus : 4|2@1- (1,0) [0|3] "" VCU
 SG_ act_Speed : 8|16@1- (1,-32000) [-32000|32255] "rpm" VCU
 SG_ act_Torque : 24|16@1- (0.2,-6400) [-6400|6451] "Nm" VCU
 SG_ at_Power : 40|16@1- (0.005,-160) [-160|161.275] "kw" VCU
 SG_ act_MotorTemperature : 56|8@1- (1,-40) [-40|210] "℃" VCU

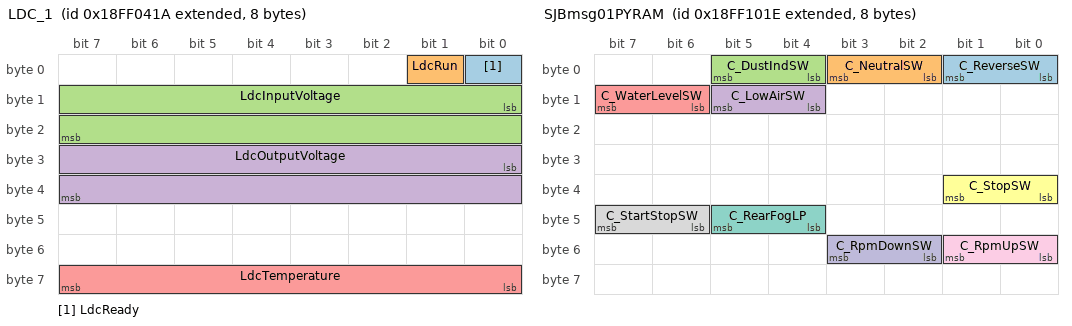
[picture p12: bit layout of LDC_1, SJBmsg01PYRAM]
BO_ 2566849562 LDC_1: 8 LDC
 SG_ LdcReady : 0|1@1+ (1,0) [0|1] "" VCU
 SG_ LdcRun : 1|1@1+ (1,0) [0|1] "" VCU
 SG_ LdcInputVoltage : 8|16@1+ (0.1,0) [0|1000] "V" VCU
 SG_ LdcOutputVoltage : 24|16@1+ (0.01,0) [0|36] "V" VCU
 SG_ LdcTemperature : 56|8@1+ (1,-40) [-40|150] "℃" VCU

BO_ 2566852638 SJBmsg01PYRAM: 8 RAM
 SG_ C_ReverseSW : 0|2@1+ (1,0) [0|3] "" VCU
 SG_ C_NeutralSW : 2|2@1+ (1,0) [0|3] "" VCU
 SG_ C_DustIndSW : 4|2@1+ (1,0) [0|3] "" VCU
 SG_ C_LowAirSW : 12|2@1+ (1,0) [0|3] "" VCU
 SG_ C_WaterLevelSW : 14|2@1+ (1,0) [0|3] "" VCU
 SG_ C_StopSW : 32|2@1+ (1,0) [0|3] "" VCU
 SG_ C_RearFogLP : 44|2@1+ (1,0) [0|3] "" VCU
 SG_ C_StartStopSW : 46|2@1+ (1,0) [0|3] "" VCU
 SG_ C_RpmUpSW : 48|2@1+ (1,0) [0|3] "" VCU
 SG_ C_RpmDownSW : 50|2@1+ (1,0) [0|3] "" VCU

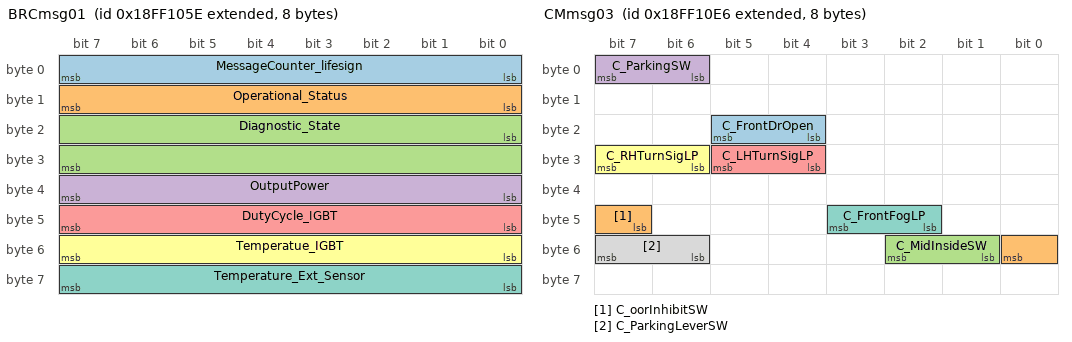
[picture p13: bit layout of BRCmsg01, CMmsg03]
BO_ 2566852702 BRCmsg01: 8 BRC
 SG_ MessageCounter_lifesign : 0|8@1+ (1,0) [0|255] "" VCU
 SG_ Operational_Status : 8|8@1+ (1,0) [0|250] "" VCU
 SG_ Diagnostic_State : 16|16@1+ (1,0) [0|64255] "" VCU
 SG_ OutputPower : 32|8@1+ (0.5,0) [0|125] "kw" VCU
 SG_ DutyCycle_IGBT : 40|8@1+ (0.4,0) [0|100] "%" VCU
 SG_ Temperatue_IGBT : 48|8@1+ (1,-40) [-40|210] "℃" VCU
 SG_ Temperature_Ext_Sensor : 56|8@1+ (1,-40) [-40|210] "K" VCU

BO_ 2566852838 CMmsg03: 8 CM
 SG_ C_FrontDrOpen : 20|2@1+ (1,0) [0|3] "" VCU
 SG_ C_oorInhibitSW : 47|2@1+ (1,0) [0|3] "" VCU
 SG_ C_MidInsideSW : 49|2@1+ (1,0) [0|3] "" VCU
 SG_ C_ParkingSW : 6|2@1+ (1,0) [0|3] "" VCU
 SG_ C_LHTurnSigLP : 28|2@1+ (1,0) [0|3] "" VCU
 SG_ C_RHTurnSigLP : 30|2@1+ (1,0) [0|3] "" VCU
 SG_ C_FrontFogLP : 42|2@1+ (1,0) [0|3] "" VCU
 SG_ C_ParkingLeverSW : 54|2@1+ (1,0) [0|3] "" VCU

BO_ 2566852864 PROSCR2: 8 VCU
 SG_ EngOperationStatus : 0|8@1+ (1,0) [0|255] "" Vector__XXX

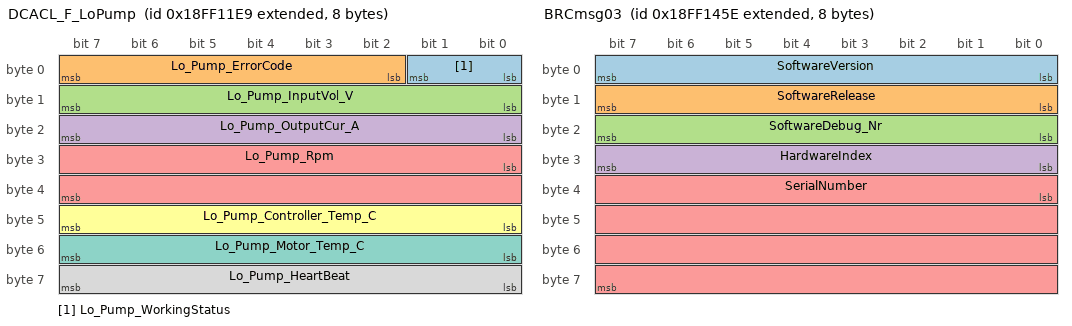
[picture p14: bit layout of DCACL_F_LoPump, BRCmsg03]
BO_ 2566853097 DCACL_F_LoPump: 8 EHPS_Lo_OilPump
 SG_ Lo_Pump_WorkingStatus : 0|2@1+ (1,0) [0|1] "" VCU
 SG_ Lo_Pump_ErrorCode : 2|6@1+ (1,0) [0|63] "" VCU
 SG_ Lo_Pump_InputVol_V : 8|8@1+ (0.2,0) [0|51] "" VCU
 SG_ Lo_Pump_OutputCur_A : 16|8@1+ (1,0) [0|51] "" VCU
 SG_ Lo_Pump_Rpm : 24|16@1+ (1,0) [0|5000] "" VCU
 SG_ Lo_Pump_Controller_Temp_C : 40|8@1+ (1,-40) [-40|210] "" VCU
 SG_ Lo_Pump_Motor_Temp_C : 48|8@1+ (1,-40) [-40|210] "" VCU
 SG_ Lo_Pump_HeartBeat : 56|8@1+ (1,0) [0|255] "" VCU

BO_ 2566853214 BRCmsg02: 8 BRC
 SG_ SupplyVoltage : 0|16@1+ (0.1,0) [0|40] "V" VCU
 SG_ DCLinkVoltage : 16|16@1+ (0.1,0) [0|1000] "V" VCU
 SG_ OutputCurrent : 32|16@1+ (0.1,0) [0|100] "A" VCU
 SG_ Reserved : 48|16@1+ (1,0) [0|255] "" VCU

BO_ 2566853615 CtrlCmd: 8 VCU
 SG_ HiPresOilPumpRun : 0|2@1+ (1,0) [0|3] "" EHPS_Hi_OilPump
 SG_ LoPresOilPumpRun : 4|2@1+ (1,0) [0|3] "" EHPS_Lo_OilPump

BO_ 2566853726 BRCmsg03: 8 BRC
 SG_ SoftwareVersion : 0|8@1+ (1,0) [0|255] "" VCU
 SG_ SoftwareRelease : 8|8@1+ (1,0) [0|255] "" VCU
 SG_ SoftwareDebug_Nr : 16|8@1+ (1,0) [0|255] "" VCU
 SG_ HardwareIndex : 24|8@1+ (1,0) [0|255] "" VCU
 SG_ SerialNumber : 32|32@1+ (1,0) [0|255] "" VCU

BO_ 2566853849 RUNNING_STATE_HiPump: 8 EHPS_Hi_OilPump
 SG_ Hi_Pump_Current_A : 0|16@1+ (0.1,0) [0|6553.5] "" VCU
 SG_ Hi_Pump_Rpm : 16|16@1+ (1,0) [0|65535] "" VCU
 SG_ Hi_Pump_ErrorCode : 56|6@1+ (1,0) [0|3] "" VCU
 SG_ Hi_Pump_WorkingStatus : 62|2@1+ (1,0) [0|3] "" VCU

BO_ 2566855407 VEH_STATE: 8 VCU
 SG_ CR_VCU_InstFuelEco_CLU3 : 0|10@1+ (0.01,0) [0|10.23] "km/kwh" Vector__XXX
 SG_ CR_VCU_DistEmpty_CLU3 : 10|10@1+ (1,0) [0|1023] "km" Vector__XXX
 SG_ CF_VCU_DteOff_CLU3 : 20|1@1+ (1,0) [0|1] "" Vector__XXX
 SG_ CF_VCU_MainRelayOpen : 21|1@1+ (1,0) [0|1] "" Vector__XXX
 SG_ CF_VCU_ChgParkingOff : 22|1@1+ (1,0) [0|1] "" Vector__XXX
 SG_ CF_VCU_AcuFault : 23|1@1+ (1,0) [0|1] "" Vector__XXX
 SG_ CF_VCU_AcuEmergOffReq : 24|1@1+ (1,0) [0|1] "" Vector__XXX
 SG_ CF_VCU_DrivingCycle_1AEF : 25|1@1+ (1,0) [0|1] "" Vector__XXX
 SG_ CF_VCU_WarmUpCycle_1AEF : 26|1@1+ (1,0) [0|1] "" Vector__XXX
 SG_ CF_VCU_AuxBraking_1AEF : 28|2@1+ (1,0) [0|3] "" Vector__XXX
 SG_ CF_VCU_StartKeySW_1AEF : 30|1@1+ (1,0) [0|1] "" Vector__XXX
 SG_ CF_VCU_SafetySW_1AEF : 31|1@1+ (1,0) [0|1] "" Vector__XXX
 SG_ CF_VCU_EVReady_1AEF : 32|2@1+ (1,0) [0|1] "" Vector__XXX
 SG_ CF_VCU_DoorSW_1AEF : 34|2@1+ (1,0) [0|3] "" Vector__XXX
 SG_ CF_VCU_IGOn_1AEF : 36|2@1+ (1,0) [0|1] "" Vector__XXX
 SG_ CR_VCU_SeqMonitor_1AEF : 40|4@1+ (1,0) [0|15] "" Vector__XXX
 SG_ CF_VCU_GearShiftInhibitReq : 44|1@1+ (1,0) [0|1] "" Vector__XXX

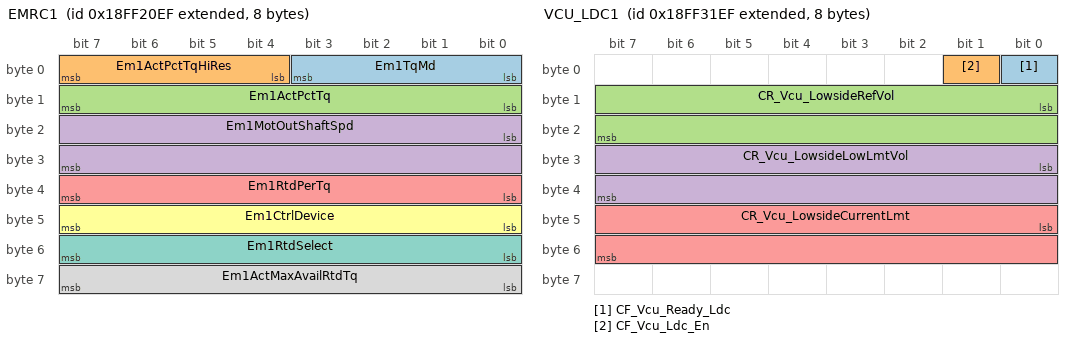
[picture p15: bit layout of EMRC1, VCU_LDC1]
BO_ 2566856943 EMRC1: 8 VCU
 SG_ Em1TqMd : 0|4@1+ (1,0) [0|15] "" Vector__XXX
 SG_ Em1ActPctTqHiRes : 4|4@1+ (1,0) [0|15] "" Vector__XXX
 SG_ Em1ActPctTq : 8|8@1+ (1,-125) [-125|125] "%" Vector__XXX
 SG_ Em1MotOutShaftSpd : 16|16@1+ (0.25,0) [0|16255.75] "rpm" Vector__XXX
 SG_ Em1RtdPerTq : 32|8@1+ (1,-125) [-125|125] "%" Vector__XXX
 SG_ Em1CtrlDevice : 40|8@1+ (1,0) [0|255] "" Vector__XXX
 SG_ Em1RtdSelect : 48|8@1+ (1,0) [0|100] "%" Vector__XXX
 SG_ Em1ActMaxAvailRtdTq : 56|8@1+ (1,-125) [-125|125] "%" Vector__XXX

BO_ 2566859503 VCU_CLUINF1: 8 VCU
 SG_ CF_VCU_MotorPower_per : 0|8@1+ (1,-100) [-100|100] "%" CLU
 SG_ CR_VCU_MSLA : 8|1@1+ (1,0) [0|1] "" Vector__XXX
 SG_ CF_VCU_CoolantAdd : 9|1@1+ (1,0) [0|1] "" CLU
 SG_ CF_VCU_PowerLimit : 10|1@1+ (1,0) [0|1] "" CLU
 SG_ CF_VCU_DteOff : 11|1@1+ (1,0) [0|1] "" Vector__XXX
 SG_ CF_VCU_BatChgFlapOpen : 12|1@1+ (1,0) [0|1] "" Vector__XXX
 SG_ CF_VCU_StartGearFault : 13|1@1+ (1,0) [0|1] "" CLU
 SG_ CF_VCU_SafetySwOn : 14|1@1+ (1,0) [0|1] "" CLU
 SG_ CF_VCU_DoorSwOn : 15|1@1+ (1,0) [0|1] "" Vector__XXX
 SG_ CF_VCU_MCUInverterFault : 16|1@1+ (1,0) [0|1] "" CLU
 SG_ CF_VCU_BatteryFault : 17|1@1+ (1,0) [0|1] "" CLU
 SG_ CF_VCU_VCUFault : 18|1@1+ (1,0) [0|1] "" CLU
 SG_ CF_VCU_AuxInverterFault : 19|1@1+ (1,0) [0|1] "" CLU
 SG_ CR_VCU_EnergyFlow : 20|4@1+ (1,0) [0|15] "" Vector__XXX
 SG_ CF_VCU_EVMode : 24|1@1+ (1,0) [0|1] "" CLU
 SG_ CF_VCU_EVModeBack : 25|1@1+ (1,0) [0|1] "" Vector__XXX
 SG_ CF_VCU_LDCFault : 26|1@1+ (1,0) [0|1] "" CLU
 SG_ CF_VCU_LowSoc : 27|1@1+ (1,0) [0|1] "" Vector__XXX
 SG_ CF_VCU_CoolantOverTemp : 28|1@1+ (1,0) [0|1] "" Vector__XXX
 SG_ CF_VCU_AuxBrake : 29|1@1+ (1,0) [0|1] "" Vector__XXX
 SG_ CF_VCU_BatteryCharge : 30|1@1+ (1,0) [0|1] "" Vector__XXX
 SG_ CF_VCU_CoolingSystemFault : 31|1@1+ (1,0) [0|1] "" CLU
 SG_ CR_VCU_CoolantTemp : 32|8@1+ (1,-40) [-40|215] "℃" Vector__XXX
 SG_ CR_VCU_InstFuelEco : 40|10@1+ (0.01,0) [0|10.23] "km/kwh" Vector__XXX
 SG_ CR_VCU_DistEmpty : 50|10@1+ (1,0) [0|1023] "km" Vector__XXX
 SG_ CF_VCU_AuxBrake2Step : 60|2@1+ (1,0) [0|3] "" CLU
 SG_ CF_VCU_CruiseCtlAct : 62|1@1+ (1,0) [0|1] "" Vector__XXX
 SG_ CF_VCU_EcoMode : 63|1@1+ (1,0) [0|1] "" Vector__XXX

BO_ 2566859759 VCU_CLUINF2: 8 VCU
 SG_ CF_VCU_Starting : 0|1@1+ (1,0) [0|1] "" Vector__XXX
 SG_ CF_VCU_ColdStart : 1|1@1+ (1,0) [0|1] "" Vector__XXX
 SG_ CF_VCU_FCReady : 2|1@1+ (1,0) [0|1] "" CLU
 SG_ CF_VCU_PowerDown : 3|1@1+ (1,0) [0|1] "" CLU
 SG_ CF_VCU_H2Warning : 4|1@1+ (1,0) [0|1] "" CLU
 SG_ CF_VCU_H2Level1Fault : 5|1@1+ (1,0) [0|1] "" CLU
 SG_ CF_VCU_H2Level2Fault : 6|1@1+ (1,0) [0|1] "" CLU
 SG_ CF_VCU_FCU1CANTout : 7|1@1+ (1,0) [0|1] "" CLU
 SG_ CF_VCU_FCU2CANTout : 8|1@1+ (1,0) [0|1] "" CLU
 SG_ CF_VCU_HMUCANTout : 9|1@1+ (1,0) [0|1] "" CLU
 SG_ CF_VCU_HDCACANTout : 10|1@1+ (1,0) [0|1] "" Vector__XXX
 SG_ CF_VCU_HDCBCANTout : 11|1@1+ (1,0) [0|1] "" Vector__XXX
 SG_ CR_VCU_FCEnergyflow : 12|4@1+ (1,0) [0|15] "" CLU
 SG_ CF_VCU_IsoResWarning : 16|1@1+ (1,0) [0|1] "" Vector__XXX
 SG_ CF_VCU_CoolantAdd_BATT : 17|1@1+ (1,0) [0|1] "" Vector__XXX
 SG_ CF_VCU_CoolantAdd_AMT : 18|1@1+ (1,0) [0|1] "" Vector__XXX
 SG_ CF_VCU_CoolantAdd_FANOIL : 19|1@1+ (1,0) [0|1] "" CLU
 SG_ CF_VCU_CoolantOverTemp_BATT : 20|1@1+ (1,0) [0|1] "" Vector__XXX
 SG_ CF_CoolingSystemFault_stk : 21|1@1+ (1,0) [0|1] "" Vector__XXX
 SG_ CF_CoolingSystemFault_BAT : 22|1@1+ (1,0) [0|1] "" Vector__XXX
 SG_ CF_CoolingSystemFault_AMT : 23|1@1+ (1,0) [0|1] "" Vector__XXX
 SG_ CF_VCU_HMU2CANTout : 26|1@1+ (1,0) [0|1] "" CLU
 SG_ CF_VCU_CoolantAdd_BrkResistor : 28|1@1+ (1,0) [0|1] "" CLU
 SG_ CF_VCU_CIntOverTemp_BrkResistor : 29|1@1+ (1,0) [0|1] "" CLU
 SG_ CF_VCU_CLSysFlt_BrkResistor : 30|1@1+ (1,0) [0|1] "" CLU
 SG_ CF_VCU_HMU3CANTout : 31|1@1+ (1,0) [0|1] "" CLU
 SG_ CR_VCU_EmerEvWarn : 32|2@1+ (1,0) [0|1] "" CLU
 SG_ CF_VCU_HighBattVoltageCharge : 34|1@1+ (1,0) [0|1] "" CLU
 SG_ CR_VCU_LowSocAlert : 35|3@1+ (1,0) [0|1] "" CLU

BO_ 2566860849 MFSMmsg01: 8 MFSM
 SG_ C_AmtPowerSW : 16|2@1+ (1,0) [0|3] "" VCU

BO_ 2566861295 VCU_LDC1: 8 VCU
 SG_ CF_Vcu_Ready_Ldc : 0|1@1+ (1,0) [0|1] "" LDC
 SG_ CF_Vcu_Ldc_En : 1|1@1+ (1,0) [0|1] "" LDC
 SG_ CR_Vcu_LowsideRefVol : 8|16@1+ (0.1,0) [0|40] "V" LDC
 SG_ CR_Vcu_LowsideLowLmtVol : 24|16@1+ (0.1,0) [0|40] "V" LDC
 SG_ CR_Vcu_LowsideCurrentLmt : 40|16@1+ (0.1,0) [0|600] "A" LDC

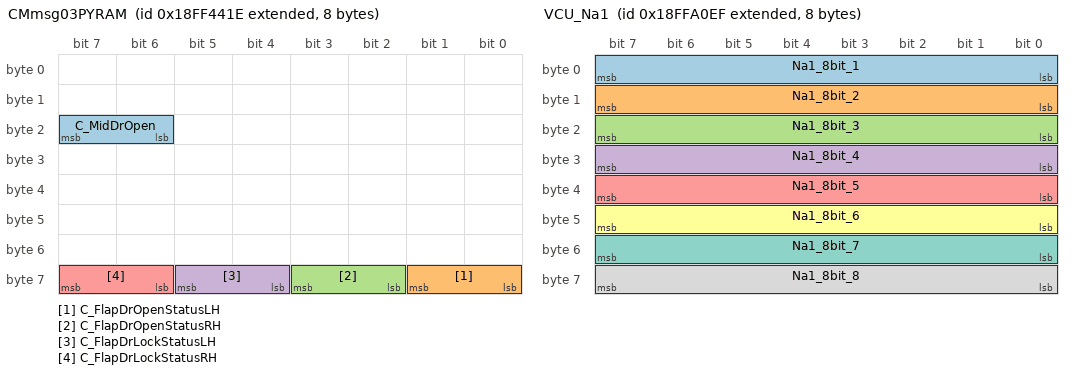
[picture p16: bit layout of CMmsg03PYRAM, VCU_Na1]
BO_ 2566865950 CMmsg03PYRAM: 8 RAM
 SG_ C_MidDrOpen : 22|2@1+ (1,0) [0|3] "" VCU
 SG_ C_FlapDrOpenStatusLH : 56|2@1+ (1,0) [0|3] "" VCU
 SG_ C_FlapDrOpenStatusRH : 58|2@1+ (1,0) [0|3] "" VCU
 SG_ C_FlapDrLockStatusLH : 60|2@1+ (1,0) [0|3] "" VCU
 SG_ C_FlapDrLockStatusRH : 62|2@1+ (1,0) [0|3] "" VCU

BO_ 2566889711 VCU_Na1: 8 VCU
 SG_ Na1_8bit_1 : 0|8@1+ (1,0) [0|255] "" Vector__XXX
 SG_ Na1_8bit_2 : 8|8@1+ (1,0) [0|255] "" Vector__XXX
 SG_ Na1_8bit_3 : 16|8@1+ (1,0) [0|255] "" Vector__XXX
 SG_ Na1_8bit_4 : 24|8@1+ (1,0) [0|255] "" Vector__XXX
 SG_ Na1_8bit_5 : 32|8@1+ (1,0) [0|255] "" Vector__XXX
 SG_ Na1_8bit_6 : 40|8@1+ (1,0) [0|255] "" Vector__XXX
 SG_ Na1_8bit_7 : 48|8@1+ (1,0) [0|255] "" Vector__XXX
 SG_ Na1_8bit_8 : 56|8@1+ (1,0) [0|255] "" Vector__XXX

BO_ 2566889768 CLU_MSG: 8 CLUSTER
 SG_ Odometer_km : 8|31@1+ (0.1,0) [0|999999.9] "km" VCU

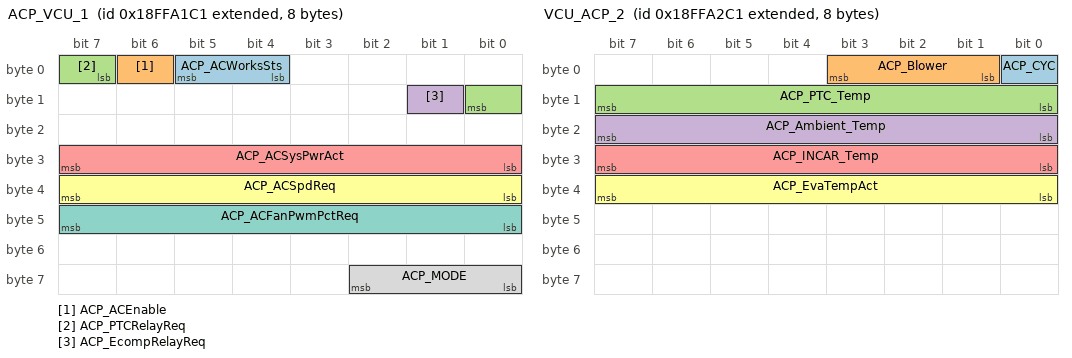
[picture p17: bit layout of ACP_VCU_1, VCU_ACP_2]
BO_ 2566889921 ACP_VCU_1: 8 ACP
 SG_ ACP_ACWorksSts : 4|2@1+ (1,0) [0|3] "" VCU
 SG_ ACP_ACEnable : 6|1@1+ (1,0) [0|1] "" VCU
 SG_ ACP_PTCRelayReq : 7|2@1+ (1,0) [0|3] "" VCU
 SG_ ACP_EcompRelayReq : 9|1@1+ (1,0) [0|1] "" VCU
 SG_ ACP_ACSysPwrAct : 24|8@1+ (0.1,0) [0|25.5] "" VCU
 SG_ ACP_ACSpdReq : 32|8@1+ (100,0) [0|8000] "rpm" VCU
 SG_ ACP_ACFanPwmPctReq : 40|8@1+ (1,0) [0|100] "%" VCU
 SG_ ACP_MODE : 56|3@1+ (1,0) [0|7] "" VCU

BO_ 2566890177 VCU_ACP_2: 8 ACP
 SG_ ACP_CYC : 0|1@1+ (1,0) [0|1] "" VCU
 SG_ ACP_Blower : 1|3@1+ (1,0) [0|7] "" VCU
 SG_ ACP_PTC_Temp : 8|8@1+ (1,-40) [-40|215] "℃" VCU
 SG_ ACP_Ambient_Temp : 16|8@1+ (0.5,-30) [-30|90] "℃" VCU
 SG_ ACP_INCAR_Temp : 24|8@1+ (0.5,-30) [-30|90] "℃" VCU
 SG_ ACP_EvaTempAct : 32|8@1+ (1,-40) [-40|210] "℃" VCU

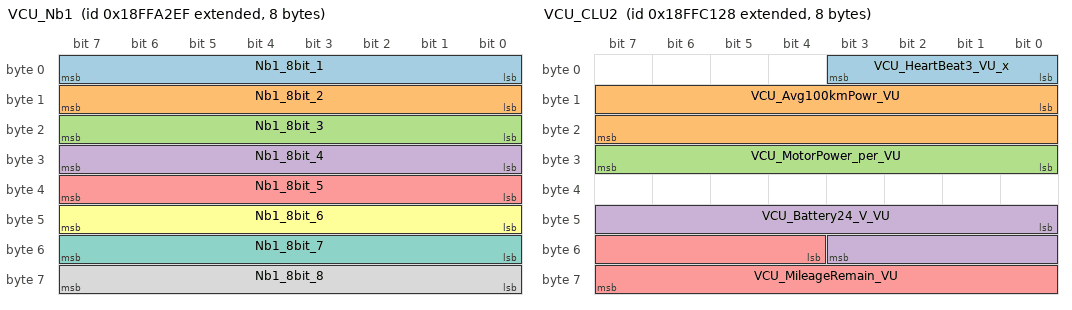
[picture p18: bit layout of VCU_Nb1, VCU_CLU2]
BO_ 2566890223 VCU_Nb1: 8 VCU
 SG_ Nb1_8bit_1 : 0|8@1+ (1,0) [0|255] "" Vector__XXX
 SG_ Nb1_8bit_2 : 8|8@1+ (1,0) [0|255] "" Vector__XXX
 SG_ Nb1_8bit_3 : 16|8@1+ (1,0) [0|255] "" Vector__XXX
 SG_ Nb1_8bit_4 : 24|8@1+ (1,0) [0|255] "" Vector__XXX
 SG_ Nb1_8bit_5 : 32|8@1+ (1,0) [0|255] "" Vector__XXX
 SG_ Nb1_8bit_6 : 40|8@1+ (1,0) [0|255] "" Vector__XXX
 SG_ Nb1_8bit_7 : 48|8@1+ (1,0) [0|255] "" Vector__XXX
 SG_ Nb1_8bit_8 : 56|8@1+ (1,0) [0|255] "" Vector__XXX

BO_ 2566893864 VCU_CLU1: 8 VCU
 SG_ VCU_Heartbeat2 : 0|4@1+ (1,0) [0|15] "" Vector__XXX
 SG_ VCU_FCReady_VF : 4|1@1+ (1,0) [0|1] "" Vector__XXX
 SG_ VCU_VehicleFaultLevel_VU : 5|3@1+ (1,0) [0|7] "" Vector__XXX
 SG_ VCU_GearLevel_VU : 8|2@1+ (1,0) [0|3] "" Vector__XXX
 SG_ VCU_BrakeFault_VF : 10|1@1+ (1,0) [0|1] "" Vector__XXX
 SG_ VCU_ShiftFailedWarning1_VF : 11|1@1+ (1,0) [0|1] "" Vector__XXX
 SG_ VCU_ShiftFailedWarning2_VF : 12|1@1+ (1,0) [0|1] "" Vector__XXX
 SG_ VCU_StartFailedWarning1_VF : 13|1@1+ (1,0) [0|1] "" Vector__XXX
 SG_ VCU_StartFailedWarning2_VF : 14|1@1+ (1,0) [0|1] "" Vector__XXX
 SG_ VCU_DriverOutAlarmWarning_VF : 15|1@1+ (1,0) [0|1] "" Vector__XXX
 SG_ VCU_DriveInhibitFailedWarning_VF : 16|1@1+ (1,0) [0|1] "" Vector__XXX
 SG_ VCU_CruiseWorkStatus_VF : 17|1@1+ (1,0) [0|1] "" Vector__XXX
 SG_ VCU_CruiseStandbyStatus_VF : 18|1@1+ (1,0) [0|1] "" Vector__XXX
 SG_ VCU_PowerLimitStatus_VF : 20|1@1+ (1,0) [0|1] "" Vector__XXX
 SG_ VCU_SeatWeightSensStatus_VF : 21|1@1+ (1,0) [0|1] "" Vector__XXX
 SG_ VCU_EcoMode_VF : 22|1@1+ (1,0) [0|1] "" Vector__XXX
 SG_ VCU_BrakePedalStatus_VF : 23|1@1+ (1,0) [0|1] "" Vector__XXX
 SG_ VCU_CruiseTargetSpeed_VU : 24|8@1+ (1,0) [0|250] "" Vector__XXX
 SG_ VCU_VehSpeed_VU : 32|8@1+ (1,0) [0|250] "" Vector__XXX
 SG_ VCU_AccelPedalPer_VU : 40|8@1+ (1,0) [0|100] "" Vector__XXX
 SG_ VCU_AuxBrake_VU : 48|2@1+ (1,0) [0|3] "" Vector__XXX
 SG_ VCU_PtoEtatus_VU : 50|2@1+ (1,0) [0|3] "" Vector__XXX
 SG_ VCU_RegenLimit_VF : 52|1@1+ (1,0) [0|1] "" Vector__XXX
 SG_ VCU_BatChg_VF : 53|1@1+ (1,0) [0|1] "" CLUSTER
 SG_ VCU_ChgParkOff_VF : 54|1@1+ (1,0) [0|1] "" Vector__XXX
 SG_ VCU_FcEnrgFlow_VU : 55|4@1+ (1,0) [0|15] "" Vector__XXX
 SG_ VCU_DteOff_VF : 59|1@1+ (1,0) [0|1] "" Vector__XXX
 SG_ VCU_HVBatChg_VF : 60|1@1+ (1,0) [0|1] "" CLUSTER
 SG_ VCU_SpdLmtWarn_VF : 61|1@1+ (1,0) [0|1] "" Vector__XXX

BO_ 2566897960 VCU_CLU2: 8 VCU
 SG_ VCU_HeartBeat3_VU_x : 0|4@1+ (1,0) [0|15] "" Vector__XXX
 SG_ VCU_Avg100kmPowr_VU : 8|16@1+ (0.01,0) [0|655.35] "" Vector__XXX
 SG_ VCU_MotorPower_per_VU : 24|8@1+ (1,-100) [-100|100] "%" Vector__XXX
 SG_ VCU_Battery24_V_VU : 40|12@1+ (0.1,0) [0|50] "" Vector__XXX
 SG_ VCU_MileageRemain_VU : 52|12@1+ (1,0) [0|1000] "" Vector__XXX

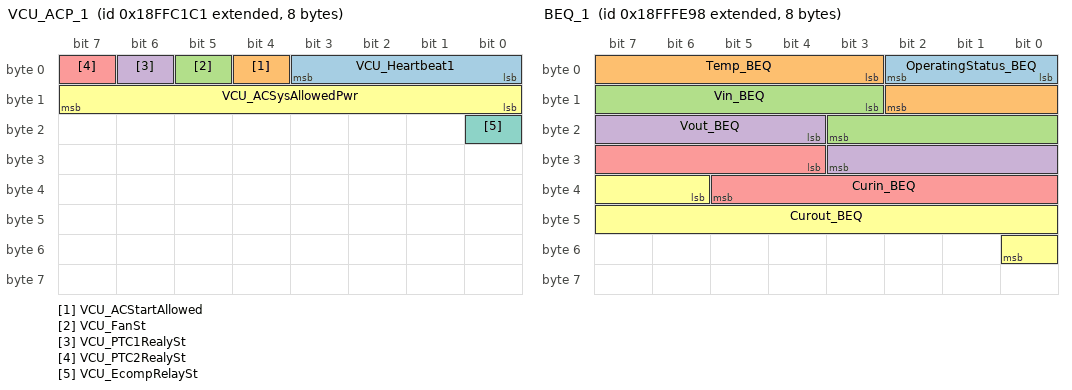
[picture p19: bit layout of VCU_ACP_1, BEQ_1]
BO_ 2566898113 VCU_ACP_1: 8 VCU
 SG_ VCU_Heartbeat1 : 0|4@1+ (1,0) [0|15] "" ACP
 SG_ VCU_ACStartAllowed : 4|1@1+ (1,0) [0|1] "" ACP
 SG_ VCU_FanSt : 5|1@1+ (1,0) [0|1] "" ACP
 SG_ VCU_PTC1RealySt : 6|1@1+ (1,0) [0|1] "" ACP
 SG_ VCU_PTC2RealySt : 7|1@1+ (1,0) [0|1] "" ACP
 SG_ VCU_ACSysAllowedPwr : 8|8@1+ (0.1,0) [0|10] "kw" ACP
 SG_ VCU_EcompRelaySt : 16|1@1+ (1,0) [0|1] "" ACP

BO_ 2566902056 VCU_CLU3: 8 VCU
 SG_ VCU_HeartBeat4_VU_x1 : 0|4@1+ (1,0) [0|15] "" Vector__XXX
 SG_ VCU_AccelPedal1STPFlt_VF : 4|1@1+ (1,0) [0|1] "" Vector__XXX
 SG_ VCU_AccelPedal1STGFlt_VF : 5|1@1+ (1,0) [0|1] "" Vector__XXX
 SG_ VCU_AccelPedal1HiVoltFlt_VF : 6|1@1+ (1,0) [0|1] "" Vector__XXX
 SG_ VCU_AccelPedal1LoVoltFlt_VF : 7|1@1+ (1,0) [0|1] "" Vector__XXX
 SG_ VCU_AccelPedal2STPFlt_VF : 8|1@1+ (1,0) [0|1] "" Vector__XXX
 SG_ VCU_AccelPedal2STGFlt_VF : 9|1@1+ (1,0) [0|1] "" Vector__XXX
 SG_ VCU_AccelPedal2HiVoltFlt_VF : 10|1@1+ (1,0) [0|1] "" Vector__XXX
 SG_ VCU_AccelPedal2LoVoltFlt_VF : 11|1@1+ (1,0) [0|1] "" Vector__XXX
 SG_ VCU_BrkPedlSTPFault_VF : 12|1@1+ (1,0) [0|1] "" Vector__XXX
 SG_ VCU_BrkPedlSTGFault_VF : 13|1@1+ (1,0) [0|1] "" Vector__XXX
 SG_ VCU_BrkPedalHiFault_VF : 14|1@1+ (1,0) [0|1] "" Vector__XXX
 SG_ VCU_BrkPedalLoFault_VF : 15|1@1+ (1,0) [0|1] "" Vector__XXX
 SG_ VCU_AccelPedalCorrFault_VF : 16|1@1+ (1,0) [0|1] "" Vector__XXX
 SG_ VCU_BrkPedalCorrFault_VF : 17|1@1+ (1,0) [0|1] "" Vector__XXX
 SG_ VCU_CoolPumpFault_VF : 18|1@1+ (1,0) [0|1] "" Vector__XXX
 SG_ VCU_CoolFanFault_VF : 19|1@1+ (1,0) [0|1] "" Vector__XXX
 SG_ VCU_AuxInvFlt_CLU3_VF : 20|1@1+ (1,0) [0|1] "" Vector__XXX
 SG_ VCU_Bat24LoVolFault_VF : 21|1@1+ (1,0) [0|1] "" Vector__XXX
 SG_ VCU_McuCANFault_VF : 22|1@1+ (1,0) [0|1] "" Vector__XXX
 SG_ VCU_LdcCANFalut_VF : 23|1@1+ (1,0) [0|1] "" Vector__XXX
 SG_ VCU_EhpsCANFault_VF : 24|1@1+ (1,0) [0|1] "" Vector__XXX
 SG_ VCU_ICCANFault_VF : 25|1@1+ (1,0) [0|1] "" Vector__XXX
 SG_ VCU_TBoxCANFault_VF : 26|1@1+ (1,0) [0|1] "" Vector__XXX
 SG_ VCU_ABSCANFault_VF : 27|1@1+ (1,0) [0|1] "" Vector__XXX
 SG_ VCU_ACCMCANFault_VF : 28|1@1+ (1,0) [0|1] "" Vector__XXX
 SG_ VCU_AVASCANFault_VF : 29|1@1+ (1,0) [0|1] "" Vector__XXX
 SG_ VCU_EGPCANFault_VF : 30|1@1+ (1,0) [0|1] "" Vector__XXX
 SG_ VCU_BMSCANFault_VF : 31|1@1+ (1,0) [0|1] "" Vector__XXX
 SG_ VCU_BMSUnHopeOpenFlt_VF : 32|1@1+ (1,0) [0|1] "" Vector__XXX
 SG_ VCU_AIOMainUnHopeOpenFlt_VF : 33|1@1+ (1,0) [0|1] "" Vector__XXX
 SG_ VCU_AIOAuxUnHopeOpenFlt_VF : 34|1@1+ (1,0) [0|1] "" Vector__XXX
 SG_ VCU_TorqueCheckFault_VF : 35|1@1+ (1,0) [0|1] "" Vector__XXX
 SG_ VCU_CruiseSwFault_VF : 36|1@1+ (1,0) [0|1] "" Vector__XXX
 SG_ VCU_FanEnbOutFault_VF : 37|1@1+ (1,0) [0|1] "" Vector__XXX
 SG_ VCU_McuOutSTPFault_VF : 38|1@1+ (1,0) [0|1] "" Vector__XXX
 SG_ VCU_McuOutSTGFault_VF : 39|1@1+ (1,0) [0|1] "" Vector__XXX
 SG_ VCU_WaterPumpFault_VF : 40|1@1+ (1,0) [0|1] "" Vector__XXX
 SG_ VCU_RearLampOutSTPFault_VF : 41|1@1+ (1,0) [0|1] "" Vector__XXX
 SG_ VCU_RearLampOutSTGFault_VF : 42|1@1+ (1,0) [0|1] "" Vector__XXX
 SG_ VCU_VcuEVFault_VF : 43|1@1+ (1,0) [0|1] "" Vector__XXX
 SG_ VCU_VcuFCEVFault_VF : 44|1@1+ (1,0) [0|1] "" Vector__XXX
 SG_ VCU_TboxDetachableWarn_VF : 45|1@1+ (1,0) [0|1] "" Vector__XXX
 SG_ VCU_VehSpdLmtLvlTBox_VU : 46|2@1+ (1,0) [0|3] "" Vector__XXX

BO_ 2566906152 VCU_CLU4: 8 VCU
 SG_ VCU_ClAdd_FanOil_VF : 0|1@1+ (1,0) [0|1] "" Vector__XXX
 SG_ VCU_CoolantOvrTemp_PE_VF : 1|1@1+ (1,0) [0|1] "" Vector__XXX
 SG_ VCU_CoolantAdd_PE_VF : 2|1@1+ (1,0) [0|1] "" Vector__XXX
 SG_ reserved1 : 3|2@1+ (1,0) [0|3] "" Vector__XXX
 SG_ VCU_ClSysFault_Stk_VF : 5|1@1+ (1,0) [0|1] "" Vector__XXX
 SG_ reserved2 : 6|2@1+ (1,0) [0|3] "" Vector__XXX
 SG_ VCU_ClSysFault_PE_VF : 8|1@1+ (1,0) [0|1] "" Vector__XXX
 SG_ VCU_StIntLckInfo_VF : 9|1@1+ (1,0) [0|1] "" Vector__XXX
 SG_ VCU_GdfFault_Fc_VF : 10|2@1+ (1,0) [0|1] "" Vector__XXX
 SG_ VCU_FcuCANFault_VF : 12|1@1+ (1,0) [0|1] "" Vector__XXX
 SG_ VCU_HMSCANFault_VF : 13|1@1+ (1,0) [0|1] "" Vector__XXX
 SG_ VCU_PowerDown_VF : 14|1@1+ (1,0) [0|1] "" Vector__XXX
 SG_ VCU_EVMode_VF : 15|1@1+ (1,0) [0|1] "" Vector__XXX
 SG_ reserved3 : 16|1@1+ (1,0) [0|1] "" Vector__XXX
 SG_ VCU_LowSocAlert_VU : 17|2@1+ (1,0) [0|3] "" Vector__XXX
 SG_ VCU_EmgEVWarning_VF : 19|2@1+ (1,0) [0|2] "" Vector__XXX
 SG_ VCU_GdfFault_EV_VF : 21|2@1+ (1,0) [0|3] "" Vector__XXX
 SG_ reserved4 : 24|16@1+ (0.01,0) [0|655.35] "mg/100ms" Vector__XXX
 SG_ reserved5 : 40|8@1+ (1,0) [0|100] "%/bit" Vector__XXX
 SG_ reserved6 : 48|8@1- (1,0) [-40|125] "℃" Vector__XXX
 SG_ reserved7 : 56|8@1- (1,0) [-40|125] "℃" Vector__XXX

BO_ 2566909946 RX_XCP_Req: 8 Tester
 SG_ Signal_XCP_Request : 0|64@1+ (1,0) [0|1.844674407371e+19] "" VCU

BO_ 2566910248 VCU_CLU5: 8 VCU
 SG_ VCU_HsVlt_VU : 0|13@1+ (0.1,0) [0|500] "V" Vector__XXX
 SG_ VCU_HsCur_VU : 16|16@1+ (0.1,0) [0|500] "A" Vector__XXX
 SG_ VCU_H2MidPrs_VU : 32|8@1+ (20,0) [0|5100] "kPa" Vector__XXX

BO_ 2566912751 TX_XCP_Req: 8 VCU
 SG_ Signal_XCP_Respose : 0|64@1+ (1,0) [0|1.844674407371e+19] "" Vector__XXX

BO_ 2566913688 BEQ_1: 8 BEQ
 SG_ OperatingStatus_BEQ : 0|3@1+ (1,0) [0|7] "" VCU
 SG_ Temp_BEQ : 3|8@1+ (1,-40) [-40|215] "℃" VCU
 SG_ Vin_BEQ : 11|9@1+ (0.1,0) [0|51.2] "V" VCU
 SG_ Vout_BEQ : 20|8@1+ (0.1,0) [0|25.6] "V" VCU
 SG_ Curin_BEQ : 28|10@1+ (0.1,0) [0|102.4] "A" VCU
 SG_ Curout_BEQ : 38|11@1+ (0.1,0) [0|204.8] "A" VCU

BO_ 2568552305 HS1: 8 EHP
 SG_ CR_HC_OutputTq : 0|16@1- (0.0625,0) [-2048|2047.939] "Nm" VCU
 SG_ CR_HC_MotorSpd : 16|16@1- (1,0) [-32768|32767] "rpm" VCU
 SG_ CR_HC_BatCurrent : 32|16@1- (1,0) [-32768|32767] "A" VCU

BO_ 2568617841 HS2: 8 EHP
 SG_ CR_HC_AvailableFwdTq : 0|16@1- (0.0626,0) [-2048|2047.939] "Nm" VCU
 SG_ CR_HC_AvailableRevTq : 16|16@1- (0.0626,0) [-2048|2047.939] "Nm" VCU
 SG_ CR_HC_Statusword : 32|4@1- (1,0) [0|15] "" VCU

BO_ 2568683377 HS3: 8 EHP
 SG_ CR_HC_HeatSinkTemp : 0|16@1- (1,0) [-32768|32767] "℃" VCU
 SG_ CR_HC_MotorTemp : 16|16@1- (1,0) [-32768|32767] "℃" VCU
 SG_ CR_HC_CapVoltage : 32|16@1- (0.0626,0) [-2048|2047] "" VCU

BO_ 2568748913 HS4: 8 EHP
 SG_ CR_HC_FaultCode : 0|16@1+ (1,0) [0|65535] "" VCU
 SG_ CR_HC_DebugBytes : 32|16@1+ (0,0) [0|0] "" VCU

BO_ 2583662831 VCUBSW_M3_BU: 8 VCU
 SG_ Aps1_C17_Min : 0|16@1+ (1,0) [0|1023] "kg/100km" Vector__XXX
 SG_ Aps1_C17_Max : 16|16@1+ (1,0) [0|1023] "kg/100km" Vector__XXX
 SG_ Aps2_C11_Min : 32|16@1+ (1,0) [0|1023] "kg/100km" Vector__XXX
 SG_ Aps2_C11_Max : 48|16@1+ (1,0) [0|1023] "kg/100km" Vector__XXX

CM_ SG_ 2566844683 FrontAxleLeftWheelSpeed "0x18FE6E0B";
CM_ SG_ 2566844683 FrontAxleRightWheelSpeed "0x18FE6E0B";
CM_ SG_ 2566844683 RearAxleLeftWheelSpeed "0x18FE6E0B";
CM_ SG_ 2566844683 RearAxleRightWheelSpeed "0x18FE6E0B";
CM_ SG_ 2566893864 VCU_BatChg_VF "충전건 제거후 시동을 거십시오";
CM_ SG_ 2566893864 VCU_ChgParkOff_VF "파킹후 충전 하십시오";
CM_ SG_ 2566893864 VCU_FcEnrgFlow_VU "Fc 에너지 flow";
CM_ SG_ 2566893864 VCU_DteOff_VF "Dte Off";
CM_ SG_ 2566893864 VCU_HVBatChg_VF "배터리 전압 낮을 때 Fc로 강제 충전";
CM_ SG_ 2566893864 VCU_SpdLmtWarn_VF "속도제한 경고등, 경고음용 신호";
CM_ SG_ 2566897960 VCU_Avg100kmPowr_VU "100km당 전기소모";
CM_ SG_ 2566897960 VCU_MotorPower_per_VU "Motor Power(%)";
CM_ SG_ 2566897960 VCU_Battery24_V_VU "24V 배터리 전압";
CM_ SG_ 2566897960 VCU_MileageRemain_VU "항속가는거리";
CM_ SG_ 2566902056 VCU_AccelPedal1STPFlt_VF "APS1 전원단락( short)";
CM_ SG_ 2566902056 VCU_AccelPedal1STGFlt_VF "APS1 접지단락( short)";
CM_ SG_ 2566902056 VCU_AccelPedal1HiVoltFlt_VF "센서1 신호가 높음";
CM_ SG_ 2566902056 VCU_AccelPedal1LoVoltFlt_VF "센서1 신호가 낮음";
CM_ SG_ 2566902056 VCU_AccelPedal2STPFlt_VF "APS2 전원단락( short)";
CM_ SG_ 2566902056 VCU_AccelPedal2STGFlt_VF "APS2 접지단락( short)";
CM_ SG_ 2566902056 VCU_AccelPedal2HiVoltFlt_VF "센서2 신호가 높음";
CM_ SG_ 2566902056 VCU_AccelPedal2LoVoltFlt_VF "센서2 신호가 낮음";
CM_ SG_ 2566902056 VCU_BrkPedlSTPFault_VF "Brake Pedal 전원 단락";
CM_ SG_ 2566902056 VCU_BrkPedlSTGFault_VF "Brake Pedal 접지 단락";
CM_ SG_ 2566902056 VCU_BrkPedalHiFault_VF "BrakePedal신호가 높다";
CM_ SG_ 2566902056 VCU_BrkPedalLoFault_VF "BrakePedal신호가 낮다";
CM_ SG_ 2566902056 VCU_AccelPedalCorrFault_VF "AccelPedal관련고장";
CM_ SG_ 2566902056 VCU_BrkPedalCorrFault_VF "BrakePedal관련고장";
CM_ SG_ 2566902056 VCU_CoolPumpFault_VF "냉각수 펌프고장";
CM_ SG_ 2566902056 VCU_CoolFanFault_VF "냉각팬고장";
CM_ SG_ 2566902056 VCU_AuxInvFlt_CLU3_VF "AuxInv(ACM)고장";
CM_ SG_ 2566902056 VCU_Bat24LoVolFault_VF "24배터리전압 저 고장";
CM_ SG_ 2566902056 VCU_McuCANFault_VF "MCU CAN Fault";
CM_ SG_ 2566902056 VCU_LdcCANFalut_VF "DCDC CAN Fault";
CM_ SG_ 2566902056 VCU_EhpsCANFault_VF "Ehps CAN Fault";
CM_ SG_ 2566902056 VCU_ICCANFault_VF "계측기 통신장애";
CM_ SG_ 2566902056 VCU_TBoxCANFault_VF "Tbox CAN Fault";
CM_ SG_ 2566902056 VCU_ABSCANFault_VF "ABS CAN Fault";
CM_ SG_ 2566902056 VCU_ACCMCANFault_VF "ACCM CAN Fault";
CM_ SG_ 2566902056 VCU_AVASCANFault_VF "AVAS CAN Fault";
CM_ SG_ 2566902056 VCU_BMSCANFault_VF "BMS CAN Fault";
CM_ SG_ 2566902056 VCU_BMSUnHopeOpenFlt_VF "BMS 메인릴레이(-) 비희망 차단";
CM_ SG_ 2566902056 VCU_AIOMainUnHopeOpenFlt_VF "올인원 메인고압회로 비희망 차단";
CM_ SG_ 2566902056 VCU_AIOAuxUnHopeOpenFlt_VF "올인원 Apu고압회로 비희망 차단";
CM_ SG_ 2566902056 VCU_TorqueCheckFault_VF "모터토크체크불량";
CM_ SG_ 2566902056 VCU_FanEnbOutFault_VF "EFAN 고장";
CM_ SG_ 2566902056 VCU_McuOutSTPFault_VF "모터제어기 단락";
CM_ SG_ 2566902056 VCU_McuOutSTGFault_VF "모터제어기 단락";
CM_ SG_ 2566902056 VCU_RearLampOutSTPFault_VF "리어램프 고장";
CM_ SG_ 2566902056 VCU_RearLampOutSTGFault_VF "리어램프 고장";
CM_ SG_ 2566902056 VCU_VcuEVFault_VF "EV고장";
CM_ SG_ 2566902056 VCU_VcuFCEVFault_VF "FCEV고장";
CM_ SG_ 2566902056 VCU_TboxDetachableWarn_VF "Tbox탈착바이 알람";
CM_ SG_ 2566902056 VCU_VehSpdLmtLvlTBox_VU "완성차 속도제란등급 적용";
CM_ SG_ 2566853615 HiPresOilPumpRun "EHPS 고압 오일펌프 가동";
CM_ SG_ 2566853615 LoPresOilPumpRun "EHPS 저압 오일펌프 가동";
CM_ SG_ 2566810647 WhkBasdSpeed "차량속도";
CM_ SG_ 2583662831 Aps1_C17_Min "BSW내부에서처리, API없음";
CM_ SG_ 2583662831 Aps1_C17_Max "BSW내부에서처리, API없음";
CM_ SG_ 2583662831 Aps2_C11_Min "BSW내부에서처리, API없음";
CM_ SG_ 2583662831 Aps2_C11_Max "BSW내부에서처리, API없음";

BA_DEF_ "BusType" STRING;
BA_DEF_ BU_ "NmStationAddress" HEX 0 255;
BA_DEF_ BO_ "VFrameFormat" ENUM "StandardCAN","ExtendedCAN","reserved","J1939PG","reserved","reserved","reserved","reserved","reserved","reserved","reserved","reserved","reserved","reserved","StandardCAN_FD","ExtendedCAN_FD";
BA_DEF_ BO_ "GenMsgCycleTime" INT 0 200000;
BA_DEF_ BO_ "GenMsgSendType" ENUM "Cyclic","NoMsgSendType";
BA_DEF_ BO_ "TpJ1939VarDlc" ENUM "No","Yes";
BA_DEF_ BO_ "GenMsgDelayTime" INT 0 1000;
BA_DEF_ BO_ "GenMsgRequestable" INT 0 1;
BA_DEF_ BO_ "GenMsgILSupport" ENUM "No","Yes";
BA_DEF_ SG_ "GenSigSendType" ENUM "NotUsed","OnWrite","OnWriteWithRepetition","OnChange","OnChangeWithRepetition","IfActive","IfActiveWithRepetition","NoSigSendType";
BA_DEF_ SG_ "GenSigStartValue" INT 0 100000;

BA_DEF_DEF_ "BusType" "CAN";
BA_DEF_DEF_ "NmStationAddress" 0;
BA_DEF_DEF_ "VFrameFormat" "StandardCAN";
BA_DEF_DEF_ "GenMsgCycleTime" 0;
BA_DEF_DEF_ "GenMsgSendType" "NoMsgSendType";
BA_DEF_DEF_ "TpJ1939VarDlc" "No";
BA_DEF_DEF_ "GenMsgDelayTime" 0;
BA_DEF_DEF_ "GenMsgRequestable" 0;
BA_DEF_DEF_ "GenMsgILSupport" "Yes";
BA_DEF_DEF_ "GenSigSendType" "NoSigSendType";
BA_DEF_DEF_ "GenSigStartValue" 0;

BA_ "NmStationAddress" BU_ VCU 239;
BA_ "NmStationAddress" BU_ EBS 11;
BA_ "NmStationAddress" BU_ CM 230;
BA_ "NmStationAddress" BU_ ACC 42;
BA_ "NmStationAddress" BU_ CAMERA 160;
BA_ "NmStationAddress" BU_ ECAS 47;
BA_ "NmStationAddress" BU_ Tester 249;
BA_ "NmStationAddress" BU_ BEQ 152;
BA_ "NmStationAddress" BU_ ACP 239;
BA_ "NmStationAddress" BU_ MFSM 49;
BA_ "NmStationAddress" BU_ CRSH 89;
BA_ "NmStationAddress" BU_ CLUSTER 40;
BA_ "NmStationAddress" BU_ EHPS_Hi_OilPump 217;
BA_ "NmStationAddress" BU_ EHPS_Lo_OilPump 233;
BA_ "NmStationAddress" BU_ LDC 26;
BA_ "NmStationAddress" BU_ EHP 113;
BA_ "NmStationAddress" BU_ EWP_1 57;
BA_ "NmStationAddress" BU_ EWP_2 58;
BA_ "NmStationAddress" BU_ EWP_3 148;
BA_ "NmStationAddress" BU_ Aux_Inv 246;
BA_ "NmStationAddress" BU_ BRC 94;
BA_ "NmStationAddress" BU_ RAM 30;
BA_ "VFrameFormat" BO_ 2364539904 1;
BA_ "GenMsgCycleTime" BO_ 2364539904 10;
BA_ "GenMsgSendType" BO_ 2364539904 0;
BA_ "GenMsgRequestable" BO_ 2364539904 1;
BA_ "VFrameFormat" BO_ 2364539648 1;
BA_ "GenMsgCycleTime" BO_ 2364539648 50;
BA_ "GenMsgSendType" BO_ 2364539648 0;
BA_ "GenMsgRequestable" BO_ 2364539648 1;
BA_ "VFrameFormat" BO_ 2566840064 1;
BA_ "GenMsgCycleTime" BO_ 2566840064 250;
BA_ "GenMsgSendType" BO_ 2566840064 0;
BA_ "GenMsgRequestable" BO_ 2566840064 1;
BA_ "VFrameFormat" BO_ 2565869551 1;
BA_ "GenMsgCycleTime" BO_ 2565869551 100;
BA_ "GenMsgSendType" BO_ 2565869551 0;
BA_ "GenMsgRequestable" BO_ 2565869551 1;
BA_ "VFrameFormat" BO_ 2565865488 1;
BA_ "GenMsgCycleTime" BO_ 2565865488 100;
BA_ "GenMsgSendType" BO_ 2565865488 0;
BA_ "GenMsgRequestable" BO_ 2565865488 1;
BA_ "VFrameFormat" BO_ 2566840591 3;
BA_ "GenMsgCycleTime" BO_ 2566840591 5000;
BA_ "GenMsgSendType" BO_ 2566840591 0;
BA_ "GenMsgRequestable" BO_ 2566840591 1;
BA_ "VFrameFormat" BO_ 2565668623 1;
BA_ "GenMsgRequestable" BO_ 2565668623 1;
BA_ "VFrameFormat" BO_ 2565603087 1;
BA_ "GenMsgRequestable" BO_ 2565603087 1;
BA_ "VFrameFormat" BO_ 2566840592 3;
BA_ "GenMsgCycleTime" BO_ 2566840592 5000;
BA_ "GenMsgSendType" BO_ 2566840592 0;
BA_ "GenMsgRequestable" BO_ 2566840592 1;
BA_ "VFrameFormat" BO_ 2565668624 1;
BA_ "GenMsgRequestable" BO_ 2565668624 1;
BA_ "VFrameFormat" BO_ 2565603088 1;
BA_ "GenMsgRequestable" BO_ 2565603088 1;
BA_ "VFrameFormat" BO_ 2566841088 3;
BA_ "GenMsgCycleTime" BO_ 2566841088 5000;
BA_ "GenMsgSendType" BO_ 2566841088 0;
BA_ "GenMsgRequestable" BO_ 2566841088 1;
BA_ "VFrameFormat" BO_ 2565668608 1;
BA_ "GenMsgRequestable" BO_ 2565668608 1;
BA_ "VFrameFormat" BO_ 2565603072 1;
BA_ "GenMsgRequestable" BO_ 2565603072 1;
BA_ "VFrameFormat" BO_ 2566811659 1;
BA_ "GenMsgRequestable" BO_ 2566811659 1;
BA_ "VFrameFormat" BO_ 2565865739 1;
BA_ "GenMsgCycleTime" BO_ 2565865739 100;
BA_ "GenMsgSendType" BO_ 2565865739 0;
BA_ "GenMsgRequestable" BO_ 2565865739 1;
BA_ "VFrameFormat" BO_ 2566831883 1;
BA_ "GenMsgCycleTime" BO_ 2566831883 100;
BA_ "GenMsgSendType" BO_ 2566831883 0;
BA_ "GenMsgRequestable" BO_ 2566831883 1;
BA_ "VFrameFormat" BO_ 2566767627 1;
BA_ "GenMsgCycleTime" BO_ 2566767627 100;
BA_ "GenMsgSendType" BO_ 2566767627 0;
BA_ "GenMsgRequestable" BO_ 2566767627 1;
BA_ "VFrameFormat" BO_ 2566844683 1;
BA_ "GenMsgCycleTime" BO_ 2566844683 20;
BA_ "GenMsgSendType" BO_ 2566844683 0;
BA_ "GenMsgRequestable" BO_ 2566844683 1;
BA_ "VFrameFormat" BO_ 2348810251 3;
BA_ "GenMsgCycleTime" BO_ 2348810251 100;
BA_ "GenMsgRequestable" BO_ 2348810251 1;
BA_ "VFrameFormat" BO_ 2348814347 3;
BA_ "GenMsgCycleTime" BO_ 2348814347 200;
BA_ "GenMsgRequestable" BO_ 2348814347 1;
BA_ "VFrameFormat" BO_ 2348814091 3;
BA_ "GenMsgCycleTime" BO_ 2348814091 200;
BA_ "GenMsgRequestable" BO_ 2348814091 1;
BA_ "VFrameFormat" BO_ 2566803211 1;
BA_ "GenMsgCycleTime" BO_ 2566803211 100;
BA_ "GenMsgSendType" BO_ 2566803211 0;
BA_ "GenMsgRequestable" BO_ 2566803211 1;
BA_ "VFrameFormat" BO_ 2565867787 1;
BA_ "GenMsgCycleTime" BO_ 2565867787 10;
BA_ "GenMsgSendType" BO_ 2565867787 0;
BA_ "GenMsgRequestable" BO_ 2565867787 1;
BA_ "VFrameFormat" BO_ 2565877003 1;
BA_ "GenMsgCycleTime" BO_ 2565877003 20;
BA_ "GenMsgSendType" BO_ 2565877003 0;
BA_ "GenMsgRequestable" BO_ 2565877003 1;
BA_ "VFrameFormat" BO_ 2566803761 1;
BA_ "GenMsgCycleTime" BO_ 2566803761 250;
BA_ "GenMsgSendType" BO_ 2566803761 0;
BA_ "GenMsgRequestable" BO_ 2566803761 1;
BA_ "VFrameFormat" BO_ 2349075242 3;
BA_ "GenMsgCycleTime" BO_ 2349075242 200;
BA_ "GenMsgSendType" BO_ 2349075242 0;
BA_ "GenMsgRequestable" BO_ 2349075242 1;
BA_ "VFrameFormat" BO_ 2349075360 3;
BA_ "GenMsgCycleTime" BO_ 2349075360 200;
BA_ "GenMsgSendType" BO_ 2349075360 0;
BA_ "GenMsgRequestable" BO_ 2349075360 1;
BA_ "VFrameFormat" BO_ 2566793775 1;
BA_ "GenMsgCycleTime" BO_ 2566793775 100;
BA_ "GenMsgSendType" BO_ 2566793775 0;
BA_ "GenMsgRequestable" BO_ 2566793775 1;
BA_ "VFrameFormat" BO_ 2348810282 3;
BA_ "GenMsgCycleTime" BO_ 2348810282 10;
BA_ "GenMsgRequestable" BO_ 2348810282 1;
BA_ "VFrameFormat" BO_ 2566844672 1;
BA_ "GenMsgCycleTime" BO_ 2566844672 100;
BA_ "GenMsgSendType" BO_ 2566844672 0;
BA_ "GenMsgRequestable" BO_ 2566844672 1;
BA_ "VFrameFormat" BO_ 2566844911 1;
BA_ "GenMsgCycleTime" BO_ 2566844911 10;
BA_ "GenMsgSendType" BO_ 2566844911 0;
BA_ "GenMsgRequestable" BO_ 2566844911 1;
BA_ "VFrameFormat" BO_ 2566708224 1;
BA_ "GenMsgCycleTime" BO_ 2566708224 1000;
BA_ "GenMsgSendType" BO_ 2566708224 0;
BA_ "GenMsgRequestable" BO_ 2566708224 1;
BA_ "VFrameFormat" BO_ 2566856943 1;
BA_ "GenMsgCycleTime" BO_ 2566856943 10;
BA_ "GenMsgSendType" BO_ 2566856943 0;
BA_ "GenMsgRequestable" BO_ 2566856943 1;
BA_ "VFrameFormat" BO_ 2565537791 1;
BA_ "GenMsgCycleTime" BO_ 2565537791 1000;
BA_ "GenMsgSendType" BO_ 2565537791 0;
BA_ "GenMsgRequestable" BO_ 2565537791 1;
BA_ "VFrameFormat" BO_ 2566834927 3;
BA_ "GenMsgCycleTime" BO_ 2566834927 1000;
BA_ "GenMsgSendType" BO_ 2566834927 0;
BA_ "TpJ1939VarDlc" BO_ 2566834927 1;
BA_ "GenMsgRequestable" BO_ 2566834927 1;
BA_ "VFrameFormat" BO_ 2565668847 1;
BA_ "GenMsgRequestable" BO_ 2565668847 1;
BA_ "VFrameFormat" BO_ 2565603311 1;
BA_ "GenMsgRequestable" BO_ 2565603311 1;
BA_ "VFrameFormat" BO_ 2566909946 1;
BA_ "GenMsgRequestable" BO_ 2566909946 1;
BA_ "VFrameFormat" BO_ 2566912751 1;
BA_ "GenMsgRequestable" BO_ 2566912751 1;
BA_ "VFrameFormat" BO_ 2499739897 1;
BA_ "GenMsgRequestable" BO_ 2499739897 1;
BA_ "VFrameFormat" BO_ 2499739887 1;
BA_ "GenMsgRequestable" BO_ 2499739887 1;
BA_ "VFrameFormat" BO_ 2566913688 1;
BA_ "GenMsgCycleTime" BO_ 2566913688 100;
BA_ "GenMsgRequestable" BO_ 2566913688 1;
BA_ "VFrameFormat" BO_ 2566898113 1;
BA_ "GenMsgCycleTime" BO_ 2566898113 100;
BA_ "GenMsgSendType" BO_ 2566898113 0;
BA_ "GenMsgRequestable" BO_ 2566898113 1;
BA_ "VFrameFormat" BO_ 2566889921 1;
BA_ "GenMsgCycleTime" BO_ 2566889921 100;
BA_ "GenMsgSendType" BO_ 2566889921 0;
BA_ "GenMsgRequestable" BO_ 2566889921 1;
BA_ "VFrameFormat" BO_ 2566890177 1;
BA_ "GenMsgCycleTime" BO_ 2566890177 100;
BA_ "GenMsgSendType" BO_ 2566890177 0;
BA_ "GenMsgRequestable" BO_ 2566890177 1;
BA_ "VFrameFormat" BO_ 2566860849 1;
BA_ "GenMsgCycleTime" BO_ 2566860849 50;
BA_ "GenMsgSendType" BO_ 2566860849 0;
BA_ "GenMsgRequestable" BO_ 2566860849 1;
BA_ "VFrameFormat" BO_ 2348876549 3;
BA_ "GenMsgCycleTime" BO_ 2348876549 50;
BA_ "GenMsgSendType" BO_ 2348876549 0;
BA_ "GenMsgRequestable" BO_ 2348876549 1;
BA_ "VFrameFormat" BO_ 2566838758 1;
BA_ "GenMsgCycleTime" BO_ 2566838758 50;
BA_ "GenMsgSendType" BO_ 2566838758 0;
BA_ "GenMsgRequestable" BO_ 2566838758 1;
BA_ "VFrameFormat" BO_ 2560814937 1;
BA_ "GenMsgCycleTime" BO_ 2560814937 250;
BA_ "GenMsgSendType" BO_ 2560814937 0;
BA_ "GenMsgRequestable" BO_ 2560814937 1;
BA_ "VFrameFormat" BO_ 2566852864 1;
BA_ "GenMsgCycleTime" BO_ 2566852864 100;
BA_ "GenMsgSendType" BO_ 2566852864 0;
BA_ "GenMsgRequestable" BO_ 2566852864 1;
BA_ "VFrameFormat" BO_ 2365484270 3;
BA_ "GenMsgCycleTime" BO_ 2365484270 50;
BA_ "GenMsgSendType" BO_ 2365484270 0;
BA_ "GenMsgRequestable" BO_ 2365484270 1;
BA_ "VFrameFormat" BO_ 2566893864 1;
BA_ "GenMsgCycleTime" BO_ 2566893864 100;
BA_ "GenMsgSendType" BO_ 2566893864 0;
BA_ "GenMsgRequestable" BO_ 2566893864 1;
BA_ "VFrameFormat" BO_ 2566897960 1;
BA_ "GenMsgCycleTime" BO_ 2566897960 200;
BA_ "GenMsgSendType" BO_ 2566897960 0;
BA_ "GenMsgRequestable" BO_ 2566897960 1;
BA_ "VFrameFormat" BO_ 2566902056 1;
BA_ "GenMsgCycleTime" BO_ 2566902056 200;
BA_ "GenMsgSendType" BO_ 2566902056 0;
BA_ "GenMsgRequestable" BO_ 2566902056 1;
BA_ "VFrameFormat" BO_ 2566906152 1;
BA_ "GenMsgCycleTime" BO_ 2566906152 200;
BA_ "GenMsgSendType" BO_ 2566906152 0;
BA_ "GenMsgRequestable" BO_ 2566906152 1;
BA_ "VFrameFormat" BO_ 2566910248 1;
BA_ "GenMsgCycleTime" BO_ 2566910248 200;
BA_ "GenMsgSendType" BO_ 2566910248 0;
BA_ "GenMsgRequestable" BO_ 2566910248 1;
BA_ "VFrameFormat" BO_ 2566889768 1;
BA_ "GenMsgCycleTime" BO_ 2566889768 200;
BA_ "GenMsgSendType" BO_ 2566889768 0;
BA_ "GenMsgRequestable" BO_ 2566889768 1;
BA_ "VFrameFormat" BO_ 2566853615 1;
BA_ "GenMsgCycleTime" BO_ 2566853615 100;
BA_ "GenMsgSendType" BO_ 2566853615 0;
BA_ "GenMsgRequestable" BO_ 2566853615 1;
BA_ "VFrameFormat" BO_ 2566810647 1;
BA_ "GenMsgCycleTime" BO_ 2566810647 100;
BA_ "GenMsgSendType" BO_ 2566810647 0;
BA_ "GenMsgRequestable" BO_ 2566810647 1;
BA_ "VFrameFormat" BO_ 2566853849 1;
BA_ "GenMsgCycleTime" BO_ 2566853849 50;
BA_ "GenMsgSendType" BO_ 2566853849 0;
BA_ "GenMsgRequestable" BO_ 2566853849 1;
BA_ "VFrameFormat" BO_ 2566853097 1;
BA_ "GenMsgCycleTime" BO_ 2566853097 100;
BA_ "GenMsgSendType" BO_ 2566853097 0;
BA_ "GenMsgRequestable" BO_ 2566853097 1;
BA_ "VFrameFormat" BO_ 2566861295 1;
BA_ "GenMsgCycleTime" BO_ 2566861295 100;
BA_ "GenMsgSendType" BO_ 2566861295 0;
BA_ "GenMsgRequestable" BO_ 2566861295 1;
BA_ "GenMsgCycleTime" BO_ 1298 100;
BA_ "GenMsgSendType" BO_ 1298 0;
BA_ "GenMsgRequestable" BO_ 1298 1;
BA_ "VFrameFormat" BO_ 2499748089 1;
BA_ "GenMsgRequestable" BO_ 2499748089 1;
BA_ "VFrameFormat" BO_ 2499748079 1;
BA_ "GenMsgRequestable" BO_ 2499748079 1;
BA_ "VFrameFormat" BO_ 2566849562 1;
BA_ "GenMsgCycleTime" BO_ 2566849562 100;
BA_ "GenMsgSendType" BO_ 2566849562 0;
BA_ "GenMsgRequestable" BO_ 2566849562 1;
BA_ "VFrameFormat" BO_ 2566889711 1;
BA_ "GenMsgCycleTime" BO_ 2566889711 10;
BA_ "GenMsgSendType" BO_ 2566889711 0;
BA_ "GenMsgRequestable" BO_ 2566889711 1;
BA_ "VFrameFormat" BO_ 2566890223 1;
BA_ "GenMsgCycleTime" BO_ 2566890223 100;
BA_ "GenMsgSendType" BO_ 2566890223 0;
BA_ "GenMsgRequestable" BO_ 2566890223 1;
BA_ "VFrameFormat" BO_ 2432593706 3;
BA_ "GenMsgCycleTime" BO_ 2432593706 100;
BA_ "GenMsgSendType" BO_ 2432593706 0;
BA_ "GenMsgRequestable" BO_ 2432593706 1;
BA_ "VFrameFormat" BO_ 2364550954 3;
BA_ "GenMsgCycleTime" BO_ 2364550954 50;
BA_ "GenMsgSendType" BO_ 2364550954 0;
BA_ "GenMsgRequestable" BO_ 2364550954 1;
BA_ "VFrameFormat" BO_ 2565865967 1;
BA_ "GenMsgCycleTime" BO_ 2565865967 100;
BA_ "GenMsgSendType" BO_ 2565865967 0;
BA_ "GenMsgRequestable" BO_ 2565865967 1;
BA_ "VFrameFormat" BO_ 2349075217 3;
BA_ "GenMsgCycleTime" BO_ 2349075217 20;
BA_ "GenMsgSendType" BO_ 2349075217 0;
BA_ "GenMsgRequestable" BO_ 2349075217 1;
BA_ "VFrameFormat" BO_ 2568552305 1;
BA_ "GenMsgCycleTime" BO_ 2568552305 200;
BA_ "GenMsgSendType" BO_ 2568552305 0;
BA_ "GenMsgRequestable" BO_ 2568552305 1;
BA_ "VFrameFormat" BO_ 2568617841 1;
BA_ "GenMsgCycleTime" BO_ 2568617841 200;
BA_ "GenMsgSendType" BO_ 2568617841 0;
BA_ "GenMsgRequestable" BO_ 2568617841 1;
BA_ "VFrameFormat" BO_ 2568683377 1;
BA_ "GenMsgCycleTime" BO_ 2568683377 200;
BA_ "GenMsgSendType" BO_ 2568683377 0;
BA_ "GenMsgRequestable" BO_ 2568683377 1;
BA_ "VFrameFormat" BO_ 2568748913 1;
BA_ "GenMsgCycleTime" BO_ 2568748913 1000;
BA_ "GenMsgSendType" BO_ 2568748913 0;
BA_ "GenMsgRequestable" BO_ 2568748913 1;
BA_ "VFrameFormat" BO_ 2566848825 1;
BA_ "GenMsgCycleTime" BO_ 2566848825 500;
BA_ "GenMsgSendType" BO_ 2566848825 0;
BA_ "GenMsgRequestable" BO_ 2566848825 1;
BA_ "VFrameFormat" BO_ 2566848826 1;
BA_ "GenMsgCycleTime" BO_ 2566848826 500;
BA_ "GenMsgSendType" BO_ 2566848826 0;
BA_ "GenMsgRequestable" BO_ 2566848826 1;
BA_ "VFrameFormat" BO_ 2566848827 1;
BA_ "GenMsgCycleTime" BO_ 2566848827 500;
BA_ "GenMsgSendType" BO_ 2566848827 0;
BA_ "GenMsgRequestable" BO_ 2566848827 1;
BA_ "VFrameFormat" BO_ 2566855407 1;
BA_ "GenMsgCycleTime" BO_ 2566855407 100;
BA_ "GenMsgSendType" BO_ 2566855407 0;
BA_ "GenMsgRequestable" BO_ 2566855407 1;
BA_ "VFrameFormat" BO_ 2566859503 1;
BA_ "GenMsgCycleTime" BO_ 2566859503 100;
BA_ "GenMsgSendType" BO_ 2566859503 0;
BA_ "GenMsgRequestable" BO_ 2566859503 1;
BA_ "VFrameFormat" BO_ 2566859759 1;
BA_ "GenMsgCycleTime" BO_ 2566859759 100;
BA_ "GenMsgSendType" BO_ 2566859759 0;
BA_ "GenMsgRequestable" BO_ 2566859759 1;
BA_ "VFrameFormat" BO_ 2566848758 1;
BA_ "GenMsgCycleTime" BO_ 2566848758 100;
BA_ "GenMsgRequestable" BO_ 2566848758 1;
BA_ "VFrameFormat" BO_ 2566849014 1;
BA_ "GenMsgCycleTime" BO_ 2566849014 100;
BA_ "GenMsgRequestable" BO_ 2566849014 1;
BA_ "VFrameFormat" BO_ 2566852702 1;
BA_ "GenMsgCycleTime" BO_ 2566852702 100;
BA_ "GenMsgRequestable" BO_ 2566852702 1;
BA_ "VFrameFormat" BO_ 2566853214 1;
BA_ "GenMsgCycleTime" BO_ 2566853214 100;
BA_ "GenMsgRequestable" BO_ 2566853214 1;
BA_ "VFrameFormat" BO_ 2566853726 1;
BA_ "GenMsgRequestable" BO_ 2566853726 1;
BA_ "VFrameFormat" BO_ 2566865950 1;
BA_ "GenMsgCycleTime" BO_ 2566865950 100;
BA_ "GenMsgRequestable" BO_ 2566865950 1;
BA_ "VFrameFormat" BO_ 2359629598 3;
BA_ "GenMsgCycleTime" BO_ 2359629598 100;
BA_ "GenMsgRequestable" BO_ 2359629598 1;
BA_ "VFrameFormat" BO_ 2566852838 1;
BA_ "GenMsgCycleTime" BO_ 2566852838 100;
BA_ "GenMsgRequestable" BO_ 2566852838 1;
BA_ "VFrameFormat" BO_ 2566852638 1;
BA_ "GenMsgCycleTime" BO_ 2566852638 200;
BA_ "GenMsgRequestable" BO_ 2566852638 1;
BA_ "VFrameFormat" BO_ 2550876911 1;
BA_ "GenMsgCycleTime" BO_ 2550876911 1000;
BA_ "GenMsgSendType" BO_ 2550876911 0;
BA_ "GenMsgRequestable" BO_ 2550876911 1;
BA_ "VFrameFormat" BO_ 2583662831 1;
BA_ "GenMsgCycleTime" BO_ 2583662831 1000;
BA_ "GenMsgSendType" BO_ 2583662831 0;
BA_ "GenMsgRequestable" BO_ 2583662831 1;
